AUTOSAR XML (schema 4-0-3)
package /ComponentTypes
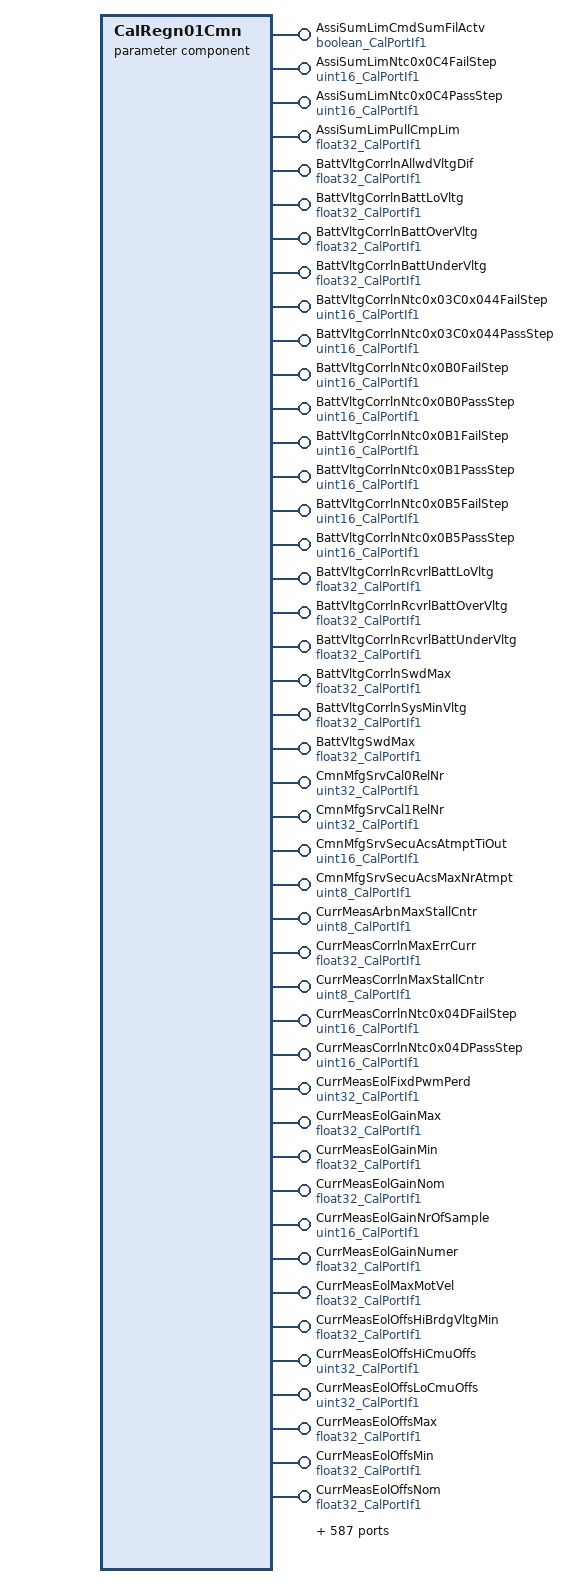
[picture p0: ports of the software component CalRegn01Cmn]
  parameter sw component type CalRegn01Cmn
    633 x provide port:
      AssiSumLimCmdSumFilActv: parameter-provide-com-spec{init-value=1, parameter=Logl}, provided-interface=boolean_CalPortIf1
      AssiSumLimNtc0x0C4FailStep: parameter-provide-com-spec{init-value=65535, parameter=Val}, provided-interface=uint16_CalPortIf1
      AssiSumLimNtc0x0C4PassStep: parameter-provide-com-spec{init-value=65535, parameter=Val}, provided-interface=uint16_CalPortIf1
      AssiSumLimPullCmpLim: parameter-provide-com-spec{init-value=8.8, parameter=Val}, provided-interface=float32_CalPortIf1
      BattVltgCorrlnAllwdVltgDif: parameter-provide-com-spec{init-value=0.73, parameter=Val}, provided-interface=float32_CalPortIf1
      BattVltgCorrlnBattLoVltg: parameter-provide-com-spec{init-value=10, parameter=Val}, provided-interface=float32_CalPortIf1
      BattVltgCorrlnBattOverVltg: parameter-provide-com-spec{init-value=16, parameter=Val}, provided-interface=float32_CalPortIf1
      BattVltgCorrlnBattUnderVltg: parameter-provide-com-spec{init-value=9, parameter=Val}, provided-interface=float32_CalPortIf1
      BattVltgCorrlnNtc0x03C0x044FailStep: parameter-provide-com-spec{init-value=410, parameter=Val}, provided-interface=uint16_CalPortIf1
      BattVltgCorrlnNtc0x03C0x044PassStep: parameter-provide-com-spec{init-value=272, parameter=Val}, provided-interface=uint16_CalPortIf1
      BattVltgCorrlnNtc0x0B0FailStep: parameter-provide-com-spec{init-value=327, parameter=Val}, provided-interface=uint16_CalPortIf1
      BattVltgCorrlnNtc0x0B0PassStep: parameter-provide-com-spec{init-value=327, parameter=Val}, provided-interface=uint16_CalPortIf1
      BattVltgCorrlnNtc0x0B1FailStep: parameter-provide-com-spec{init-value=327, parameter=Val}, provided-interface=uint16_CalPortIf1
      BattVltgCorrlnNtc0x0B1PassStep: parameter-provide-com-spec{init-value=327, parameter=Val}, provided-interface=uint16_CalPortIf1
      BattVltgCorrlnNtc0x0B5FailStep: parameter-provide-com-spec{init-value=327, parameter=Val}, provided-interface=uint16_CalPortIf1
      BattVltgCorrlnNtc0x0B5PassStep: parameter-provide-com-spec{init-value=327, parameter=Val}, provided-interface=uint16_CalPortIf1
      BattVltgCorrlnRcvrlBattLoVltg: parameter-provide-com-spec{init-value=10.5, parameter=Val}, provided-interface=float32_CalPortIf1
      BattVltgCorrlnRcvrlBattOverVltg: parameter-provide-com-spec{init-value=15.5, parameter=Val}, provided-interface=float32_CalPortIf1
      BattVltgCorrlnRcvrlBattUnderVltg: parameter-provide-com-spec{init-value=9.5, parameter=Val}, provided-interface=float32_CalPortIf1
      BattVltgCorrlnSwdMax: parameter-provide-com-spec{init-value=16, parameter=Val}, provided-interface=float32_CalPortIf1
      BattVltgCorrlnSysMinVltg: parameter-provide-com-spec{init-value=6, parameter=Val}, provided-interface=float32_CalPortIf1
      BattVltgSwdMax: parameter-provide-com-spec{init-value=16, parameter=Val}, provided-interface=float32_CalPortIf1
      CmnMfgSrvCal0RelNr: parameter-provide-com-spec{init-value=0, parameter=Val}, provided-interface=uint32_CalPortIf1
      CmnMfgSrvCal1RelNr: parameter-provide-com-spec{init-value=0, parameter=Val}, provided-interface=uint32_CalPortIf1
      CmnMfgSrvSecuAcsAtmptTiOut: parameter-provide-com-spec{init-value=0, parameter=Val}, provided-interface=uint16_CalPortIf1
      CmnMfgSrvSecuAcsMaxNrAtmpt: parameter-provide-com-spec{init-value=0, parameter=Val}, provided-interface=uint8_CalPortIf1
      CurrMeasArbnMaxStallCntr: parameter-provide-com-spec{init-value=20, parameter=Val}, provided-interface=uint8_CalPortIf1
      CurrMeasCorrlnMaxErrCurr: parameter-provide-com-spec{init-value=12, parameter=Val}, provided-interface=float32_CalPortIf1
      CurrMeasCorrlnMaxStallCntr: parameter-provide-com-spec{init-value=200, parameter=Val}, provided-interface=uint8_CalPortIf1
      CurrMeasCorrlnNtc0x04DFailStep: parameter-provide-com-spec{init-value=512, parameter=Val}, provided-interface=uint16_CalPortIf1
      CurrMeasCorrlnNtc0x04DPassStep: parameter-provide-com-spec{init-value=512, parameter=Val}, provided-interface=uint16_CalPortIf1
      CurrMeasEolFixdPwmPerd: parameter-provide-com-spec{init-value=62500, parameter=Val}, provided-interface=uint32_CalPortIf1
      CurrMeasEolGainMax: parameter-provide-com-spec{init-value=76, parameter=Val}, provided-interface=float32_CalPortIf1
      CurrMeasEolGainMin: parameter-provide-com-spec{init-value=56, parameter=Val}, provided-interface=float32_CalPortIf1
      CurrMeasEolGainNom: parameter-provide-com-spec{init-value=66.66, parameter=Val}, provided-interface=float32_CalPortIf1
      CurrMeasEolGainNrOfSample: parameter-provide-com-spec{init-value=5, parameter=Val}, provided-interface=uint16_CalPortIf1
      CurrMeasEolGainNumer: parameter-provide-com-spec{init-value=45, parameter=Val}, provided-interface=float32_CalPortIf1
      CurrMeasEolMaxMotVel: parameter-provide-com-spec{init-value=16, parameter=Val}, provided-interface=float32_CalPortIf1
      CurrMeasEolOffsHiBrdgVltgMin: parameter-provide-com-spec{init-value=262500, parameter=Val}, provided-interface=float32_CalPortIf1
      CurrMeasEolOffsHiCmuOffs: parameter-provide-com-spec{init-value=50000, parameter=Val}, provided-interface=uint32_CalPortIf1
      CurrMeasEolOffsLoCmuOffs: parameter-provide-com-spec{init-value=6250, parameter=Val}, provided-interface=uint32_CalPortIf1
      CurrMeasEolOffsMax: parameter-provide-com-spec{init-value=2.8, parameter=Val}, provided-interface=float32_CalPortIf1
      CurrMeasEolOffsMin: parameter-provide-com-spec{init-value=2.3, parameter=Val}, provided-interface=float32_CalPortIf1
      CurrMeasEolOffsNom: parameter-provide-com-spec{init-value=2.5, parameter=Val}, provided-interface=float32_CalPortIf1
      CurrMeasEolOffsNrOfSample: parameter-provide-com-spec{init-value=20, parameter=Val}, provided-interface=uint16_CalPortIf1
      CurrMeasEolTranCntrThd: parameter-provide-com-spec{init-value=5, parameter=Val}, provided-interface=uint8_CalPortIf1
      CurrMeasMinRqrdPhaOnTi: parameter-provide-com-spec{init-value=11000, parameter=Val}, provided-interface=uint32_CalPortIf1
      CurrMeasMotAgCompuDly: parameter-provide-com-spec{init-value=30000, parameter=Val}, provided-interface=uint32_CalPortIf1
      CurrMeasMotCurrAdcVlyWrmIninMax: parameter-provide-com-spec{init-value=3, parameter=Val}, provided-interface=float32_CalPortIf1
      CurrMeasMotCurrAdcVlyWrmIninMin: parameter-provide-com-spec{init-value=2, parameter=Val}, provided-interface=float32_CalPortIf1
      CurrMeasNtc0x05DFailStep: parameter-provide-com-spec{init-value=16384, parameter=Val}, provided-interface=uint16_CalPortIf1
      CurrMeasNtc0x05DPassStep: parameter-provide-com-spec{init-value=16384, parameter=Val}, provided-interface=uint16_CalPortIf1
      DiagcMgrFltResp: parameter-provide-com-spec{init-value=[0, 34560, 34560, 34560, 34560, 34560, 34560, 34560, 34560, 34560, 34560, 34560, 34560, 34560, 34560, 34560, 34560, 34560, 34560, 34560, 34560, 34560, 34560, 34560, 34560, 34560, 34560, 34560, 34560, 34560, 34560, 34560, 34560, 34560, 34560, 34560, 34560, 34560, 34560, 34560, 34560, 34560, 34560, 34560, 34560, 34560, 34560, 34560, 34560, 34560, 34560, 34560, 34560, 34560, 34560, 34560, 34560, 34560, 34560, 34560, 34560, 34560, 34560, 34560, 34560, 34560, 34560, 34560, 34560, 34560, 34560, 34560, 34560, 34560, 34560, 34560, 34560, 34560, 34560, 34560, 34560, 34560, 34560, 34560, 34560, 34560, 34560, 34560, 34560, 34560, 34560, 34560, 34560, 34560, 34560, 34560, 34560, 34560, 34560, 34560, 34560, 34560, 34560, 34560, 34560, 34560, 34560, 34560, 34560, 34560, 34560, 34560, 34560, 34560, 34560, 34560, 34560, 34560, 34560, 34560, 34560, 34560, 34560, 34560, 34560, 34560, 34560, 34560, 34560, 34560, 34560, 34560, 34560, 34560, 34560, 34560, 34560, 34560, 34560, 34560, 34560, 34560, 34560, 34560, 34560, 34560, 34560, 34560, 34560, 34560, 34560, 34560, 34560, 34560, 34560, 34560, 34560, 34560, 34560, 34560, 34560, 34560, 34560, 34560, 34560, 34560, 34560, 34560, 34560, 34560, 34560, 34560, 34560, 34560, 34560, 34560, 34560, 34560, 34560, 34560, 34560, 34560, 34560, 34560, 34560, 34560, 34560, 34560, 34560, 34560, 34560, 34560, 34560, 34560, 34560, 34560, 34560, 34560, 34560, 34560, 34560, 34560, 34560, 34560, 34560, 34560, 34560, 34560, 34560, 34560, 34560, 34560, 34560, 34560, 34560, 34560, 34560, 34560, 34560, 34560, 34560, 34560, 34560, 34560, 34560, 34560, 34560, 34560, 34560, 34560, 34560, 34560, 34560, 34560, 34560, 34560, 34560, 34560, 34560, 34560, 34560, 34560, 34560, 34560, 34560, 34560, 34560, 34560, 34560, 34560, 34560, 34560, 34560, 34560, 34560, 34560, 34560, 34560, 34560, 34560, 34560, 34560, 34560, 34560, 34560, 34560, 34560, 34560, 34560, 34560, 34560, 34560, 34560, 34560, 34560, 34560, 34560, 34560, 34560, 34560, 34560, 34560, 34560, 34560, 34560, 34560, 34560, 34560, 34560, 34560, 34560, 34560, 34560, 34560, 34560, 34560, 34560, 34560, 34560, 34560, 34560, 34560, 34560, 34560, 34560, 34560, 34560, 34560, 34560, 34560, 34560, 34560, 34560, 34560, 34560, 34560, 34560, 34560, 34560, 34560, 34560, 34560, 34560, 34560, 34560, 34560, 34560, 34560, 34560, 34560, 34560, 34560, 34560, 34560, 34560, 34560, 34560, 34560, 34560, 34560, 34560, 34560, 34560, 34560, 34560, 34560, 34560, 34560, 34560, 34560, 34560, 34560, 34560, 34560, 34560, 34560, 34560, 34560, 34560, 34560, 34560, 34560, 34560, 34560, 34560, 34560, 34560, 34560, 34560, 34560, 34560, 34560, 34560, 34560, 34560, 34560, 34560, 34560, 34560, 34560, 34560, 34560, 34560, 34560, 34560, 34560, 34560, 34560, 34560, 34560, 34560, 34560, 34560, 34560, 34560, 34560, 34560, 34560, 34560, 34560, 34560, 34560, 34560, 34560, 34560, 34560, 34560, 34560, 34560, 34560, 34560, 34560, 34560, 34560, 34560, 34560, 34560, 34560, 34560, 34560, 34560, 34560, 34560, 34560, 34560, 34560, 34560, 34560, 34560, 34560, 34560, 34560, 34560, 34560, 34560, 34560, 34560, 34560, 34560, 34560, 34560, 34560, 34560, 34560, 34560, 34560, 34560, 34560, 34560, 34560, 34560, 34560, 34560, 34560, 34560, 34560, 34560, 34560, 34560, 34560, 34560, 34560, 34560, 34560, 34560, 34560, 34560, 34560, 34560, 34560, 34560, 34560, 34560, 34560, 34560, 34560, 34560, 34560, 34560, 34560, 34560, 34560, 34560, 34560, 34560, 34560, 34560, 34560, 34560, 34560, 34560, 34560, 34560, 34560, 34560, 34560, 34560, 34560, 34560, 34560, 34560, 34560, 34560, 34560, 34560, 34560, 34560, 34560, 34560, 34560, 34560, 34560], parameter=Ary1D}, provided-interface=Ary1D_u16_512_CalPortIf1
      DrvrTqEstimnMtrxA: parameter-provide-com-spec{init-value=[[-0.17159, 0.00010352, 1.1696, 0.00024516, 1.9834e-05], [-240.58, 0.060289, 240.53, 0.17028, 0.047148], [0.0018246, -4.2826e-06, 0.99616, 0.00025897, -2.8965e-07], [-6.1943, 0.014635, 5.9127, 0.11656, 0.00098854], [-70.875, -0.28572, 70.86, 0.053221, 0.98679]], parameter=Ary2D}, provided-interface=Ary2D_f32_5_5_CalPortIf1
      DrvrTqEstimnMtrxB: parameter-provide-com-spec{init-value=[[3.2994e-07, 0.0081464, 0.0019034, 0.0016485], [0.00045434, 1.6329, 0.0015119, 0.76734], [1.1488e-06, -2.4566e-05, 0.0019002, 0.001743], [0.0027499, 0.045004, 0.00025007, 0.86756], [0.0001448, 0.50816, -2.5948e-05, 0.23299]], parameter=Ary2D}, provided-interface=Ary2D_f32_5_4_CalPortIf1
      DrvrTqEstimnMtrxC: parameter-provide-com-spec{init-value=[0, 0, 0, 0, 1], parameter=Ary1D}, provided-interface=Ary1D_f32_5_CalPortIf1
      DrvrTqEstimnMtrxD: parameter-provide-com-spec{init-value=[0, 0, 0, 0], parameter=Ary1D}, provided-interface=Ary1D_f32_4_CalPortIf1
      DutyCycThermProtnAbsltCtrlTFetMtgtnTblX: parameter-provide-com-spec{init-value=[122, 123, 125, 127], parameter=Ary1D}, provided-interface=Ary1D_s15p0_4_CalPortIf1
      DutyCycThermProtnAbsltCtrlTTblX: parameter-provide-com-spec{init-value=[122, 123, 125, 127], parameter=Ary1D}, provided-interface=Ary1D_s15p0_4_CalPortIf1
      DutyCycThermProtnAbsltCtrlTTqFetMtgtnTblY: parameter-provide-com-spec{init-value=[346, 287, 234, 0], parameter=Ary1D}, provided-interface=Ary1D_u9p7_4_CalPortIf1
      DutyCycThermProtnAbsltCtrlTTqTblY: parameter-provide-com-spec{init-value=[346, 287, 234, 0], parameter=Ary1D}, provided-interface=Ary1D_u9p7_4_CalPortIf1
      DutyCycThermProtnAbsltCuTFetMtgtnTblX: parameter-provide-com-spec{init-value=[122, 123, 125, 127], parameter=Ary1D}, provided-interface=Ary1D_s15p0_4_CalPortIf1
      DutyCycThermProtnAbsltCuTTblX: parameter-provide-com-spec{init-value=[122, 123, 125, 127], parameter=Ary1D}, provided-interface=Ary1D_s15p0_4_CalPortIf1
      DutyCycThermProtnAbsltCuTTqFetMtgtnTblY: parameter-provide-com-spec{init-value=[346, 287, 234, 0], parameter=Ary1D}, provided-interface=Ary1D_u9p7_4_CalPortIf1
      DutyCycThermProtnAbsltCuTTqTblY: parameter-provide-com-spec{init-value=[346, 287, 234, 0], parameter=Ary1D}, provided-interface=Ary1D_u9p7_4_CalPortIf1
      DutyCycThermProtnAbsltMotVelBreakPt: parameter-provide-com-spec{init-value=1.375, parameter=Val}, provided-interface=float32_CalPortIf1
      DutyCycThermProtnAbsltTTqSlewHiLim: parameter-provide-com-spec{init-value=0.3, parameter=Val}, provided-interface=float32_CalPortIf1
      DutyCycThermProtnAbsltTTqSlewLoLim: parameter-provide-com-spec{init-value=0.3, parameter=Val}, provided-interface=float32_CalPortIf1
      DutyCycThermProtnCtrlT: parameter-provide-com-spec{init-value=70, parameter=Val}, provided-interface=float32_CalPortIf1
      DutyCycThermProtnCtrlTSeln: parameter-provide-com-spec{init-value=1, parameter=Logl}, provided-interface=boolean_CalPortIf1
      DutyCycThermProtnDutyCycFildThd: parameter-provide-com-spec{init-value=92, parameter=Val}, provided-interface=u16p0_CalPortIf1
      DutyCycThermProtnIgnOffCtrlEna: parameter-provide-com-spec{init-value=0, parameter=Logl}, provided-interface=boolean_CalPortIf1
      DutyCycThermProtnIgnOffMsgWaitTi: parameter-provide-com-spec{init-value=0.5, parameter=Val}, provided-interface=float32_CalPortIf1
      DutyCycThermProtnLstTblValNonStall: parameter-provide-com-spec{init-value=[[128, 128, 128, 44, 44], [128, 128, 128, 44, 44]], parameter=Ary2D}, provided-interface=Ary2D_u9p7_2_5_CalPortIf1
      DutyCycThermProtnLstTblValStall: parameter-provide-com-spec{init-value=[[124, 124, 124, 40, 40], [124, 124, 124, 40, 40]], parameter=Ary2D}, provided-interface=Ary2D_u9p7_2_5_CalPortIf1
      DutyCycThermProtnMotPrTSeln: parameter-provide-com-spec{init-value=1, parameter=Logl}, provided-interface=boolean_CalPortIf1
      DutyCycThermProtnMplr1FetMtgtnNonStallTblY: parameter-provide-com-spec{init-value=[127, 127, 127, 1630, 1630], parameter=Ary1D}, provided-interface=Ary1D_u3p13_5_CalPortIf1
      DutyCycThermProtnMplr1FetMtgtnStallTblY: parameter-provide-com-spec{init-value=[133, 133, 133, 180, 180], parameter=Ary1D}, provided-interface=Ary1D_u3p13_5_CalPortIf1
      DutyCycThermProtnMplr1NonStallTblY: parameter-provide-com-spec{init-value=[127, 127, 127, 1630, 1630], parameter=Ary1D}, provided-interface=Ary1D_u3p13_5_CalPortIf1
      DutyCycThermProtnMplr1StallTblY: parameter-provide-com-spec{init-value=[133, 133, 133, 180, 180], parameter=Ary1D}, provided-interface=Ary1D_u3p13_5_CalPortIf1
      DutyCycThermProtnMplr2FetMtgtnNonStallTblY: parameter-provide-com-spec{init-value=[159, 159, 159, 281, 281], parameter=Ary1D}, provided-interface=Ary1D_u3p13_5_CalPortIf1
      DutyCycThermProtnMplr2FetMtgtnStallTblY: parameter-provide-com-spec{init-value=[167, 167, 167, 310, 310], parameter=Ary1D}, provided-interface=Ary1D_u3p13_5_CalPortIf1
      DutyCycThermProtnMplr2NonStallTblY: parameter-provide-com-spec{init-value=[159, 159, 159, 281, 281], parameter=Ary1D}, provided-interface=Ary1D_u3p13_5_CalPortIf1
      DutyCycThermProtnMplr2StallTblY: parameter-provide-com-spec{init-value=[167, 167, 167, 310, 310], parameter=Ary1D}, provided-interface=Ary1D_u3p13_5_CalPortIf1
      DutyCycThermProtnMplr3FetMtgtnNonStallTblY: parameter-provide-com-spec{init-value=[199, 199, 199, 1282, 1282], parameter=Ary1D}, provided-interface=Ary1D_u3p13_5_CalPortIf1
      DutyCycThermProtnMplr3FetMtgtnStallTblY: parameter-provide-com-spec{init-value=[210, 210, 210, 1707, 1707], parameter=Ary1D}, provided-interface=Ary1D_u3p13_5_CalPortIf1
      DutyCycThermProtnMplr3NonStallTblY: parameter-provide-com-spec{init-value=[199, 199, 199, 1282, 1282], parameter=Ary1D}, provided-interface=Ary1D_u3p13_5_CalPortIf1
      DutyCycThermProtnMplr3StallTblY: parameter-provide-com-spec{init-value=[210, 210, 210, 1707, 1707], parameter=Ary1D}, provided-interface=Ary1D_u3p13_5_CalPortIf1
      DutyCycThermProtnMplr4FetMtgtnNonStallTblY: parameter-provide-com-spec{init-value=5 x 1, parameter=Ary1D}, provided-interface=Ary1D_u3p13_5_CalPortIf1
      DutyCycThermProtnMplr4FetMtgtnStallTblY: parameter-provide-com-spec{init-value=5 x 1, parameter=Ary1D}, provided-interface=Ary1D_u3p13_5_CalPortIf1
      DutyCycThermProtnMplr4NonStallTblY: parameter-provide-com-spec{init-value=5 x 1, parameter=Ary1D}, provided-interface=Ary1D_u3p13_5_CalPortIf1
      DutyCycThermProtnMplr4StallTblY: parameter-provide-com-spec{init-value=5 x 1, parameter=Ary1D}, provided-interface=Ary1D_u3p13_5_CalPortIf1
      DutyCycThermProtnMplr5FetMtgtnNonStallTblY: parameter-provide-com-spec{init-value=[998, 998, 998, 9535, 9535], parameter=Ary1D}, provided-interface=Ary1D_u3p13_5_CalPortIf1
      DutyCycThermProtnMplr5FetMtgtnStallTblY: parameter-provide-com-spec{init-value=[998, 998, 998, 9535, 9535], parameter=Ary1D}, provided-interface=Ary1D_u3p13_5_CalPortIf1
      DutyCycThermProtnMplr5NonStallTblY: parameter-provide-com-spec{init-value=[998, 998, 998, 9535, 9535], parameter=Ary1D}, provided-interface=Ary1D_u3p13_5_CalPortIf1
      DutyCycThermProtnMplr5StallTblY: parameter-provide-com-spec{init-value=[998, 998, 998, 9535, 9535], parameter=Ary1D}, provided-interface=Ary1D_u3p13_5_CalPortIf1
      DutyCycThermProtnMplr6FetMtgtnNonStallTblY: parameter-provide-com-spec{init-value=5 x 1, parameter=Ary1D}, provided-interface=Ary1D_u3p13_5_CalPortIf1
      DutyCycThermProtnMplr6FetMtgtnStallTblY: parameter-provide-com-spec{init-value=5 x 1, parameter=Ary1D}, provided-interface=Ary1D_u3p13_5_CalPortIf1
      DutyCycThermProtnMplr6NonStallTblY: parameter-provide-com-spec{init-value=5 x 1, parameter=Ary1D}, provided-interface=Ary1D_u3p13_5_CalPortIf1
      DutyCycThermProtnMplr6StallTblY: parameter-provide-com-spec{init-value=5 x 1, parameter=Ary1D}, provided-interface=Ary1D_u3p13_5_CalPortIf1
      DutyCycThermProtnMplrFetMtgtnTblX: parameter-provide-com-spec{init-value=[-40, 0, 83, 84, 85], parameter=Ary1D}, provided-interface=Ary1D_s15p0_5_CalPortIf1
      DutyCycThermProtnMplrTblX: parameter-provide-com-spec{init-value=[-40, 0, 83, 84, 85], parameter=Ary1D}, provided-interface=Ary1D_s15p0_5_CalPortIf1
      DutyCycThermProtnMplrTSeln: parameter-provide-com-spec{init-value=1, parameter=Logl}, provided-interface=boolean_CalPortIf1
      DutyCycThermProtnSlowFilTSeln: parameter-provide-com-spec{init-value=0, parameter=Logl}, provided-interface=boolean_CalPortIf1
      DutyCycThermProtnThermLimScaFac: parameter-provide-com-spec{init-value=0.5, parameter=Val}, provided-interface=float32_CalPortIf1
      DutyCycThermProtnThermLoadLimTblX: parameter-provide-com-spec{init-value=[[0, 76, 80, 84, 88, 92, 96, 100], [0, 76, 80, 84, 88, 92, 96, 100]], parameter=Ary2D}, provided-interface=Ary2D_u16p0_2_8_CalPortIf1
      DutyCycThermProtnThermLoadLimTblY: parameter-provide-com-spec{init-value=[[346, 346, 346, 346, 287, 234, 181, 128], [346, 346, 346, 346, 287, 234, 181, 128]], parameter=Ary2D}, provided-interface=Ary2D_u9p7_2_8_CalPortIf1
      DutyCycThermProtnTqCmdSlewDwn: parameter-provide-com-spec{init-value=0.3, parameter=Val}, provided-interface=float32_CalPortIf1
      DutyCycThermProtnTqCmdSlewUp: parameter-provide-com-spec{init-value=0.3, parameter=Val}, provided-interface=float32_CalPortIf1
      ElecPwrCnsCtrlrInpR: parameter-provide-com-spec{init-value=0.0005, parameter=Val}, provided-interface=float32_CalPortIf1
      FordMsg077BusHiSpdCanDtcInhbThd: parameter-provide-com-spec{init-value=2000, parameter=Val}, provided-interface=u16p0_CalPortIf1
      FordMsg077BusHiSpdLatACmpdInvldSigFaildThd: parameter-provide-com-spec{init-value=0, parameter=Val}, provided-interface=u16p0_CalPortIf1
      FordMsg077BusHiSpdLatACmpdInvldSigPassdThd: parameter-provide-com-spec{init-value=0, parameter=Val}, provided-interface=u16p0_CalPortIf1
      FordMsg077BusHiSpdLatACmpdVldMissThd: parameter-provide-com-spec{init-value=100, parameter=Val}, provided-interface=u16p0_CalPortIf1
      FordMsg077BusHiSpdLgtACmpdInvldSigFaildThd: parameter-provide-com-spec{init-value=0, parameter=Val}, provided-interface=u16p0_CalPortIf1
      FordMsg077BusHiSpdLgtACmpdInvldSigPassdThd: parameter-provide-com-spec{init-value=0, parameter=Val}, provided-interface=u16p0_CalPortIf1
      FordMsg077BusHiSpdLgtACmpdVldMissThd: parameter-provide-com-spec{init-value=100, parameter=Val}, provided-interface=u16p0_CalPortIf1
      FordMsg077BusHiSpdMissMsgFaildThd: parameter-provide-com-spec{init-value=100, parameter=Val}, provided-interface=u16p0_CalPortIf1
      FordMsg077BusHiSpdMissMsgPassdThd: parameter-provide-com-spec{init-value=0, parameter=Val}, provided-interface=u16p0_CalPortIf1
      FordMsg077BusHiSpdOverGndInvldSigFaildThd: parameter-provide-com-spec{init-value=0, parameter=Val}, provided-interface=u16p0_CalPortIf1
      FordMsg077BusHiSpdOverGndInvldSigPassdThd: parameter-provide-com-spec{init-value=0, parameter=Val}, provided-interface=u16p0_CalPortIf1
      FordMsg077BusHiSpdVehLatACmpdVldFaildThd: parameter-provide-com-spec{init-value=0, parameter=Val}, provided-interface=u16p0_CalPortIf1
      FordMsg077BusHiSpdVehLatACmpdVldPassdThd: parameter-provide-com-spec{init-value=5000, parameter=Val}, provided-interface=u16p0_CalPortIf1
      FordMsg077BusHiSpdVehLgtACmpdVldFaildThd: parameter-provide-com-spec{init-value=0, parameter=Val}, provided-interface=u16p0_CalPortIf1
      FordMsg077BusHiSpdVehLgtACmpdVldPassdThd: parameter-provide-com-spec{init-value=500, parameter=Val}, provided-interface=u16p0_CalPortIf1
      FordMsg077BusHiSpdVehSpdOverGndVldFaildThd: parameter-provide-com-spec{init-value=0, parameter=Val}, provided-interface=u16p0_CalPortIf1
      FordMsg077BusHiSpdVehSpdOverGndVldMissThd: parameter-provide-com-spec{init-value=100, parameter=Val}, provided-interface=u16p0_CalPortIf1
      FordMsg077BusHiSpdVehSpdOverGndVldPassdThd: parameter-provide-com-spec{init-value=0, parameter=Val}, provided-interface=u16p0_CalPortIf1
      FordMsg077BusHiSpdVehYawRateCmpdVldFaildThd: parameter-provide-com-spec{init-value=0, parameter=Val}, provided-interface=u16p0_CalPortIf1
      FordMsg077BusHiSpdVehYawRateCmpdVldPassdThd: parameter-provide-com-spec{init-value=5000, parameter=Val}, provided-interface=u16p0_CalPortIf1
      FordMsg077BusHiSpdYawRateCmpdInvldSigFaildThd: parameter-provide-com-spec{init-value=0, parameter=Val}, provided-interface=u16p0_CalPortIf1
      FordMsg077BusHiSpdYawRateCmpdInvldSigPassdThd: parameter-provide-com-spec{init-value=0, parameter=Val}, provided-interface=u16p0_CalPortIf1
      FordMsg077BusHiSpdYawRateCmpdVldMissThd: parameter-provide-com-spec{init-value=100, parameter=Val}, provided-interface=u16p0_CalPortIf1
      FordMsg07DBusHiSpdActBrkTqSigInvldPassdThd: parameter-provide-com-spec{init-value=0, parameter=Val}, provided-interface=uint16_CalPortIf1
      FordMsg07DBusHiSpdFordVehActBrkTqInvldThd: parameter-provide-com-spec{init-value=0, parameter=Val}, provided-interface=uint16_CalPortIf1
      FordMsg07DBusHiSpdFordVehActBrkTqVldThd: parameter-provide-com-spec{init-value=0, parameter=Val}, provided-interface=uint16_CalPortIf1
      FordMsg07DBusHiSpdFordVehBrkTqVldMissMsgThd: parameter-provide-com-spec{init-value=5000, parameter=Val}, provided-interface=uint16_CalPortIf1
      FordMsg07DBusHiSpdFordVehVertACmpdSigInvldThd: parameter-provide-com-spec{init-value=0, parameter=Val}, provided-interface=uint16_CalPortIf1
      FordMsg07DBusHiSpdFordVehVertACmpdSigVldThd: parameter-provide-com-spec{init-value=5000, parameter=Val}, provided-interface=uint16_CalPortIf1
      FordMsg07DBusHiSpdFordVehVertAVldMissMsgThd: parameter-provide-com-spec{init-value=5000, parameter=Val}, provided-interface=uint16_CalPortIf1
      FordMsg07DBusHiSpdMissMsgFaildThd: parameter-provide-com-spec{init-value=5000, parameter=Val}, provided-interface=uint16_CalPortIf1
      FordMsg07DBusHiSpdMissMsgPassdThd: parameter-provide-com-spec{init-value=0, parameter=Val}, provided-interface=uint16_CalPortIf1
      FordMsg07DBusHiSpdVehActTqBrkInvldFaildThd: parameter-provide-com-spec{init-value=0, parameter=Val}, provided-interface=uint16_CalPortIf1
      FordMsg07DBusHiSpdVertACmpdSigInvldFaildThd: parameter-provide-com-spec{init-value=0, parameter=Val}, provided-interface=uint16_CalPortIf1
      FordMsg07DBusHiSpdVertACmpdSigInvldPassdThd: parameter-provide-com-spec{init-value=0, parameter=Val}, provided-interface=uint16_CalPortIf1
      FordMsg083BusHiSpdFordVehTurnSigVldThd: parameter-provide-com-spec{init-value=0, parameter=Val}, provided-interface=uint16_CalPortIf1
      FordMsg083BusHiSpdMissMsgFaildThd: parameter-provide-com-spec{init-value=5000, parameter=Val}, provided-interface=uint16_CalPortIf1
      FordMsg083BusHiSpdMissMsgPassdThd: parameter-provide-com-spec{init-value=0, parameter=Val}, provided-interface=uint16_CalPortIf1
      FordMsg083BusHiSpdVehTurnSigVldMissMsgThd: parameter-provide-com-spec{init-value=5000, parameter=Val}, provided-interface=uint16_CalPortIf1
      FordMsg091BusHiSpdInvldMsgFaildThd: parameter-provide-com-spec{init-value=0, parameter=Val}, provided-interface=uint16_CalPortIf1
      FordMsg091BusHiSpdInvldMsgPassdThd: parameter-provide-com-spec{init-value=0, parameter=Val}, provided-interface=uint16_CalPortIf1
      FordMsg091BusHiSpdMissMsgFaildThd: parameter-provide-com-spec{init-value=100, parameter=Val}, provided-interface=uint16_CalPortIf1
      FordMsg091BusHiSpdMissMsgPassdThd: parameter-provide-com-spec{init-value=0, parameter=Val}, provided-interface=uint16_CalPortIf1
      FordMsg091BusHiSpdYawRateRawVldMissFaildThd: parameter-provide-com-spec{init-value=100, parameter=Val}, provided-interface=uint16_CalPortIf1
      FordMsg091BusHiSpdYawRateRawVldSigFaildThd: parameter-provide-com-spec{init-value=0, parameter=Val}, provided-interface=uint16_CalPortIf1
      FordMsg091BusHiSpdYawRateRawVldSigPassdThd: parameter-provide-com-spec{init-value=5000, parameter=Val}, provided-interface=uint16_CalPortIf1
      FordMsg167BusHiSpdMissMsgFaildTiThd: parameter-provide-com-spec{init-value=100, parameter=Val}, provided-interface=uint16_CalPortIf1
      FordMsg167BusHiSpdMissMsgPassdTiThd: parameter-provide-com-spec{init-value=0, parameter=Val}, provided-interface=uint16_CalPortIf1
      FordMsg167BusHiSpdPrpnWhlTqFaildTiThd: parameter-provide-com-spec{init-value=5000, parameter=Val}, provided-interface=uint16_CalPortIf1
      FordMsg167BusHiSpdPrpnWhlTqMissTiThd: parameter-provide-com-spec{init-value=0, parameter=Val}, provided-interface=uint16_CalPortIf1
      FordMsg167BusHiSpdPrpnWhlTqPassdTiThd: parameter-provide-com-spec{init-value=5000, parameter=Val}, provided-interface=uint16_CalPortIf1
      FordMsg167BusHiSpdPrpnWhlTqSigInvldFaildTiThd: parameter-provide-com-spec{init-value=0, parameter=Val}, provided-interface=uint16_CalPortIf1
      FordMsg167BusHiSpdPrpnWhlTqSigInvldPassdTiThd: parameter-provide-com-spec{init-value=0, parameter=Val}, provided-interface=uint16_CalPortIf1
      FordMsg202BusHiSpdEngModLoQlyVldFaildThd: parameter-provide-com-spec{init-value=0, parameter=Val}, provided-interface=uint16_CalPortIf1
      FordMsg202BusHiSpdEngModLoQlyVldMissThd: parameter-provide-com-spec{init-value=100, parameter=Val}, provided-interface=uint16_CalPortIf1
      FordMsg202BusHiSpdEngModLoQlyVldPassdThd: parameter-provide-com-spec{init-value=0, parameter=Val}, provided-interface=uint16_CalPortIf1
      FordMsg202BusHiSpdEngModlVldFaildThd: parameter-provide-com-spec{init-value=0, parameter=Val}, provided-interface=uint16_CalPortIf1
      FordMsg202BusHiSpdEngModlVldMissThd: parameter-provide-com-spec{init-value=100, parameter=Val}, provided-interface=uint16_CalPortIf1
      FordMsg202BusHiSpdGearRvsStsInvldFaildThd: parameter-provide-com-spec{init-value=0, parameter=Val}, provided-interface=uint16_CalPortIf1
      FordMsg202BusHiSpdGearRvsStsInvldPassdThd: parameter-provide-com-spec{init-value=0, parameter=Val}, provided-interface=uint16_CalPortIf1
      FordMsg202BusHiSpdGearRvsStsVldFaildThd: parameter-provide-com-spec{init-value=0, parameter=Val}, provided-interface=uint16_CalPortIf1
      FordMsg202BusHiSpdGearRvsStsVldMissThd: parameter-provide-com-spec{init-value=100, parameter=Val}, provided-interface=uint16_CalPortIf1
      FordMsg202BusHiSpdGearRvsStsVldPassdThd: parameter-provide-com-spec{init-value=0, parameter=Val}, provided-interface=uint16_CalPortIf1
      FordMsg202BusHiSpdMissMsgFaildAbsPrsntDisadThd: parameter-provide-com-spec{init-value=100, parameter=Val}, provided-interface=uint16_CalPortIf1
      FordMsg202BusHiSpdMissMsgFaildAbsPrsntEnadThd: parameter-provide-com-spec{init-value=100, parameter=Val}, provided-interface=uint16_CalPortIf1
      FordMsg202BusHiSpdMissMsgPassdThd: parameter-provide-com-spec{init-value=100, parameter=Val}, provided-interface=uint16_CalPortIf1
      FordMsg202BusHiSpdQlyFacEngModInvldFaildThd: parameter-provide-com-spec{init-value=0, parameter=Val}, provided-interface=uint16_CalPortIf1
      FordMsg202BusHiSpdQlyFacEngModInvldPassdThd: parameter-provide-com-spec{init-value=0, parameter=Val}, provided-interface=uint16_CalPortIf1
      FordMsg202BusHiSpdTrlrBackupAssiAvlVldMissThd: parameter-provide-com-spec{init-value=100, parameter=Val}, provided-interface=uint16_CalPortIf1
      FordMsg202BusHiSpdTrlrBackupAssiAvlVldPassdThd: parameter-provide-com-spec{init-value=0, parameter=Val}, provided-interface=uint16_CalPortIf1
      FordMsg213BusHiSpdAbsActvVldFaildThd: parameter-provide-com-spec{init-value=200, parameter=Val}, provided-interface=uint16_CalPortIf1
      FordMsg213BusHiSpdAbsActvVldPassdThd: parameter-provide-com-spec{init-value=0, parameter=Val}, provided-interface=uint16_CalPortIf1
      FordMsg213BusHiSpdEvasSteerAssiEnadThd: parameter-provide-com-spec{init-value=200, parameter=Val}, provided-interface=uint16_CalPortIf1
      FordMsg213BusHiSpdMissMsgFaildThd: parameter-provide-com-spec{init-value=5000, parameter=Val}, provided-interface=uint16_CalPortIf1
      FordMsg213BusHiSpdMissMsgPassdThd: parameter-provide-com-spec{init-value=0, parameter=Val}, provided-interface=uint16_CalPortIf1
      FordMsg215BusHiSpdFordVehTrlrAidModReqVldNotRxdTiThd: parameter-provide-com-spec{init-value=5000, parameter=Val}, provided-interface=uint16_CalPortIf1
      FordMsg215BusHiSpdFordVehTrlrAidModReqVldRxdTiThd: parameter-provide-com-spec{init-value=0, parameter=Val}, provided-interface=uint16_CalPortIf1
      FordMsg215BusHiSpdMissMsgFaildTiThd: parameter-provide-com-spec{init-value=5000, parameter=Val}, provided-interface=uint16_CalPortIf1
      FordMsg215BusHiSpdMissMsgPassdTiThd: parameter-provide-com-spec{init-value=0, parameter=Val}, provided-interface=uint16_CalPortIf1
      FordMsg216BusHiSpdFrntLeWhlCntrDirFaildTiThd: parameter-provide-com-spec{init-value=0, parameter=Val}, provided-interface=uint16_CalPortIf1
      FordMsg216BusHiSpdFrntLeWhlCntrDirPassdTiThd: parameter-provide-com-spec{init-value=0, parameter=Val}, provided-interface=uint16_CalPortIf1
      FordMsg216BusHiSpdFrntLeWhlVldMissMsgThd: parameter-provide-com-spec{init-value=5000, parameter=Val}, provided-interface=uint16_CalPortIf1
      FordMsg216BusHiSpdFrntRiWhlCntrDirFaildTiThd: parameter-provide-com-spec{init-value=0, parameter=Val}, provided-interface=uint16_CalPortIf1
      FordMsg216BusHiSpdFrntRiWhlCntrDirPassdTiThd: parameter-provide-com-spec{init-value=0, parameter=Val}, provided-interface=uint16_CalPortIf1
      FordMsg216BusHiSpdFrntRiWhlVldMissMsgThd: parameter-provide-com-spec{init-value=5000, parameter=Val}, provided-interface=uint16_CalPortIf1
      FordMsg216BusHiSpdMissMsgFaildTiThd: parameter-provide-com-spec{init-value=5000, parameter=Val}, provided-interface=uint16_CalPortIf1
      FordMsg216BusHiSpdMissMsgPassdTiThd: parameter-provide-com-spec{init-value=0, parameter=Val}, provided-interface=uint16_CalPortIf1
      FordMsg216BusHiSpdReLeWhlCntrDirFaildTiThd: parameter-provide-com-spec{init-value=0, parameter=Val}, provided-interface=uint16_CalPortIf1
      FordMsg216BusHiSpdReLeWhlCntrDirPassdTiThd: parameter-provide-com-spec{init-value=0, parameter=Val}, provided-interface=uint16_CalPortIf1
      FordMsg216BusHiSpdReLeWhlVldMissMsgThd: parameter-provide-com-spec{init-value=5000, parameter=Val}, provided-interface=uint16_CalPortIf1
      FordMsg216BusHiSpdReRiWhlCntrDirFaildTiThd: parameter-provide-com-spec{init-value=0, parameter=Val}, provided-interface=uint16_CalPortIf1
      FordMsg216BusHiSpdReRiWhlCntrDirPassdTiThd: parameter-provide-com-spec{init-value=0, parameter=Val}, provided-interface=uint16_CalPortIf1
      FordMsg216BusHiSpdReRiWhlVldMissMsgThd: parameter-provide-com-spec{init-value=5000, parameter=Val}, provided-interface=uint16_CalPortIf1
      FordMsg217BusHiSpdFrntLeWhlSpdInvldFaildThd: parameter-provide-com-spec{init-value=0, parameter=Val}, provided-interface=u16p0_CalPortIf1
      FordMsg217BusHiSpdFrntLeWhlSpdInvldPassdThd: parameter-provide-com-spec{init-value=0, parameter=Val}, provided-interface=u16p0_CalPortIf1
      FordMsg217BusHiSpdFrntLeWhlVldFaildThd: parameter-provide-com-spec{init-value=0, parameter=Val}, provided-interface=u16p0_CalPortIf1
      FordMsg217BusHiSpdFrntLeWhlVldMissThd: parameter-provide-com-spec{init-value=100, parameter=Val}, provided-interface=u16p0_CalPortIf1
      FordMsg217BusHiSpdFrntLeWhlVldPassdThd: parameter-provide-com-spec{init-value=0, parameter=Val}, provided-interface=u16p0_CalPortIf1
      FordMsg217BusHiSpdFrntRiWhlSpdInvldFaildThd: parameter-provide-com-spec{init-value=0, parameter=Val}, provided-interface=u16p0_CalPortIf1
      FordMsg217BusHiSpdFrntRiWhlSpdInvldPassdThd: parameter-provide-com-spec{init-value=0, parameter=Val}, provided-interface=u16p0_CalPortIf1
      FordMsg217BusHiSpdFrntRiWhlVldFaildThd: parameter-provide-com-spec{init-value=0, parameter=Val}, provided-interface=u16p0_CalPortIf1
      FordMsg217BusHiSpdFrntRiWhlVldMissThd: parameter-provide-com-spec{init-value=100, parameter=Val}, provided-interface=u16p0_CalPortIf1
      FordMsg217BusHiSpdFrntRiWhlVldPassdThd: parameter-provide-com-spec{init-value=0, parameter=Val}, provided-interface=u16p0_CalPortIf1
      FordMsg217BusHiSpdMissMsgFaildThd: parameter-provide-com-spec{init-value=100, parameter=Val}, provided-interface=u16p0_CalPortIf1
      FordMsg217BusHiSpdMissMsgPassdThd: parameter-provide-com-spec{init-value=0, parameter=Val}, provided-interface=u16p0_CalPortIf1
      FordMsg217BusHiSpdReLeWhlSpdInvldFaildThd: parameter-provide-com-spec{init-value=0, parameter=Val}, provided-interface=u16p0_CalPortIf1
      FordMsg217BusHiSpdReLeWhlSpdInvldPassdThd: parameter-provide-com-spec{init-value=0, parameter=Val}, provided-interface=u16p0_CalPortIf1
      FordMsg217BusHiSpdReLeWhlVldFaildThd: parameter-provide-com-spec{init-value=0, parameter=Val}, provided-interface=u16p0_CalPortIf1
      FordMsg217BusHiSpdReLeWhlVldMissThd: parameter-provide-com-spec{init-value=100, parameter=Val}, provided-interface=u16p0_CalPortIf1
      FordMsg217BusHiSpdReLeWhlVldPassdThd: parameter-provide-com-spec{init-value=0, parameter=Val}, provided-interface=u16p0_CalPortIf1
      FordMsg217BusHiSpdReRiWhlSpdInvldFaildThd: parameter-provide-com-spec{init-value=0, parameter=Val}, provided-interface=u16p0_CalPortIf1
      FordMsg217BusHiSpdReRiWhlSpdInvldPassdThd: parameter-provide-com-spec{init-value=0, parameter=Val}, provided-interface=u16p0_CalPortIf1
      FordMsg217BusHiSpdReRiWhlVldFaildThd: parameter-provide-com-spec{init-value=0, parameter=Val}, provided-interface=u16p0_CalPortIf1
      FordMsg217BusHiSpdReRiWhlVldMissThd: parameter-provide-com-spec{init-value=100, parameter=Val}, provided-interface=u16p0_CalPortIf1
      FordMsg217BusHiSpdReRiWhlVldPassdThd: parameter-provide-com-spec{init-value=0, parameter=Val}, provided-interface=u16p0_CalPortIf1
      FordMsg230BusHiSpdFordVehGearLvrPosnFaildTiThd: parameter-provide-com-spec{init-value=0, parameter=Val}, provided-interface=uint16_CalPortIf1
      FordMsg230BusHiSpdFordVehGearLvrPosnPassdTiThd: parameter-provide-com-spec{init-value=0, parameter=Val}, provided-interface=uint16_CalPortIf1
      FordMsg230BusHiSpdGearLvrPosnMissTiThd: parameter-provide-com-spec{init-value=5000, parameter=Val}, provided-interface=uint16_CalPortIf1
      FordMsg230BusHiSpdInvldSigFaildThd: parameter-provide-com-spec{init-value=0, parameter=Val}, provided-interface=uint16_CalPortIf1
      FordMsg230BusHiSpdInvldSigPassdThd: parameter-provide-com-spec{init-value=0, parameter=Val}, provided-interface=uint16_CalPortIf1
      FordMsg230BusHiSpdMissMsgFaildThd: parameter-provide-com-spec{init-value=5000, parameter=Val}, provided-interface=uint16_CalPortIf1
      FordMsg230BusHiSpdMissMsgPassdThd: parameter-provide-com-spec{init-value=0, parameter=Val}, provided-interface=uint16_CalPortIf1
      FordMsg2FDBusHiSpdFordVehEvasSteerAssiReqVldNotRxdTiThd: parameter-provide-com-spec{init-value=5000, parameter=Val}, provided-interface=uint16_CalPortIf1
      FordMsg2FDBusHiSpdFordVehEvasSteerAssiReqVldRxdTiThd: parameter-provide-com-spec{init-value=5000, parameter=Val}, provided-interface=uint16_CalPortIf1
      FordMsg2FDBusHiSpdMissMsgFaildTiThd: parameter-provide-com-spec{init-value=5000, parameter=Val}, provided-interface=uint16_CalPortIf1
      FordMsg2FDBusHiSpdMissMsgPassdTiThd: parameter-provide-com-spec{init-value=0, parameter=Val}, provided-interface=uint16_CalPortIf1
      FordMsg3B3BusHiSpdIgnStsVldFaildThd: parameter-provide-com-spec{init-value=0, parameter=Val}, provided-interface=u16p0_CalPortIf1
      FordMsg3B3BusHiSpdIgnStsVldMissThd: parameter-provide-com-spec{init-value=100, parameter=Val}, provided-interface=u16p0_CalPortIf1
      FordMsg3B3BusHiSpdIgnStsVldPassdThd: parameter-provide-com-spec{init-value=0, parameter=Val}, provided-interface=u16p0_CalPortIf1
      FordMsg3B3BusHiSpdInvldSigFaildThd: parameter-provide-com-spec{init-value=0, parameter=Val}, provided-interface=u16p0_CalPortIf1
      FordMsg3B3BusHiSpdInvldSigPassdThd: parameter-provide-com-spec{init-value=0, parameter=Val}, provided-interface=u16p0_CalPortIf1
      FordMsg3B3BusHiSpdMissMsgFaildThd: parameter-provide-com-spec{init-value=100, parameter=Val}, provided-interface=u16p0_CalPortIf1
      FordMsg3B3BusHiSpdMissMsgPassdThd: parameter-provide-com-spec{init-value=0, parameter=Val}, provided-interface=u16p0_CalPortIf1
      FordMsg3CABusHiSpdLaneAssiImgProcgModlAFaildCrvtTiThd: parameter-provide-com-spec{init-value=0, parameter=Val}, provided-interface=uint16_CalPortIf1
      FordMsg3CABusHiSpdLaneAssiImgProcgModlAFaildReqdAgTiThd: parameter-provide-com-spec{init-value=0, parameter=Val}, provided-interface=uint16_CalPortIf1
      FordMsg3CABusHiSpdLaneAssiImgProcgModlAPassdTiThd: parameter-provide-com-spec{init-value=5000, parameter=Val}, provided-interface=uint16_CalPortIf1
      FordMsg3CABusHiSpdLaneAssiImgProcgModlAVldMissTiThd: parameter-provide-com-spec{init-value=1000, parameter=Val}, provided-interface=uint16_CalPortIf1
      FordMsg3CABusHiSpdLaneKeepSysCrvtInvldFaildTiThd: parameter-provide-com-spec{init-value=0, parameter=Val}, provided-interface=uint16_CalPortIf1
      FordMsg3CABusHiSpdLaneKeepSysCrvtInvldPassdTiThd: parameter-provide-com-spec{init-value=0, parameter=Val}, provided-interface=uint16_CalPortIf1
      FordMsg3CABusHiSpdLaneKeepSysReqdAgInvldFaildTiThd: parameter-provide-com-spec{init-value=0, parameter=Val}, provided-interface=uint16_CalPortIf1
      FordMsg3CABusHiSpdLaneKeepSysReqdAgInvldPassdTiThd: parameter-provide-com-spec{init-value=0, parameter=Val}, provided-interface=uint16_CalPortIf1
      FordMsg3CABusHiSpdMissMsgFaildTiThd: parameter-provide-com-spec{init-value=1000, parameter=Val}, provided-interface=uint16_CalPortIf1
      FordMsg3CABusHiSpdMissMsgPassdTiThd: parameter-provide-com-spec{init-value=0, parameter=Val}, provided-interface=uint16_CalPortIf1
      FordMsg3D3BusHiSpdImgProcrModlAVldFaildThd: parameter-provide-com-spec{init-value=1000, parameter=Val}, provided-interface=uint16_CalPortIf1
      FordMsg3D3BusHiSpdImgProcrModlAVldPassdThd: parameter-provide-com-spec{init-value=5000, parameter=Val}, provided-interface=uint16_CalPortIf1
      FordMsg3D3BusHiSpdMissMsgFaildThd: parameter-provide-com-spec{init-value=1000, parameter=Val}, provided-interface=uint16_CalPortIf1
      FordMsg3D3BusHiSpdMissMsgPassdThd: parameter-provide-com-spec{init-value=0, parameter=Val}, provided-interface=uint16_CalPortIf1
      FordMsg3D7BusHiSpdImgProcrModlAVldMissThd: parameter-provide-com-spec{init-value=500, parameter=Val}, provided-interface=uint16_CalPortIf1
      FordMsg3D7BusHiSpdImgProcrModlAVldPassdThd: parameter-provide-com-spec{init-value=5000, parameter=Val}, provided-interface=uint16_CalPortIf1
      FordMsg3D7BusHiSpdLatDstInvldFaildThd: parameter-provide-com-spec{init-value=0, parameter=Val}, provided-interface=uint16_CalPortIf1
      FordMsg3D7BusHiSpdLatDstInvldPassdThd: parameter-provide-com-spec{init-value=0, parameter=Val}, provided-interface=uint16_CalPortIf1
      FordMsg3D7BusHiSpdLatDstRawVldFaildThd: parameter-provide-com-spec{init-value=0, parameter=Val}, provided-interface=uint16_CalPortIf1
      FordMsg3D7BusHiSpdLgtDstInvldFaildThd: parameter-provide-com-spec{init-value=0, parameter=Val}, provided-interface=uint16_CalPortIf1
      FordMsg3D7BusHiSpdLgtDstInvldPassdThd: parameter-provide-com-spec{init-value=0, parameter=Val}, provided-interface=uint16_CalPortIf1
      FordMsg3D7BusHiSpdLgtDstRawVldFaildThd: parameter-provide-com-spec{init-value=0, parameter=Val}, provided-interface=uint16_CalPortIf1
      FordMsg3D7BusHiSpdMissMsgFaildThd: parameter-provide-com-spec{init-value=500, parameter=Val}, provided-interface=uint16_CalPortIf1
      FordMsg3D7BusHiSpdMissMsgPassdThd: parameter-provide-com-spec{init-value=0, parameter=Val}, provided-interface=uint16_CalPortIf1
      FordMsg3D7BusHiSpdRelLatVelInvldFaildThd: parameter-provide-com-spec{init-value=0, parameter=Val}, provided-interface=uint16_CalPortIf1
      FordMsg3D7BusHiSpdRelLatVelInvldPassdThd: parameter-provide-com-spec{init-value=0, parameter=Val}, provided-interface=uint16_CalPortIf1
      FordMsg3D7BusHiSpdRelLatVelRawVldFaildThd: parameter-provide-com-spec{init-value=0, parameter=Val}, provided-interface=uint16_CalPortIf1
      FordMsg3D7BusHiSpdRelLgtVelInvldFaildThd: parameter-provide-com-spec{init-value=0, parameter=Val}, provided-interface=uint16_CalPortIf1
      FordMsg3D7BusHiSpdRelLgtVelInvldPassdThd: parameter-provide-com-spec{init-value=0, parameter=Val}, provided-interface=uint16_CalPortIf1
      FordMsg3D7BusHiSpdRelLgtVelRawVldFaildThd: parameter-provide-com-spec{init-value=0, parameter=Val}, provided-interface=uint16_CalPortIf1
      FordMsg3D7BusHiSpdTiToCllsnInvldFaildThd: parameter-provide-com-spec{init-value=0, parameter=Val}, provided-interface=uint16_CalPortIf1
      FordMsg3D7BusHiSpdTiToCllsnInvldPassdThd: parameter-provide-com-spec{init-value=0, parameter=Val}, provided-interface=uint16_CalPortIf1
      FordMsg3D7BusHiSpdTiToCllsnRawVldFaildThd: parameter-provide-com-spec{init-value=0, parameter=Val}, provided-interface=uint16_CalPortIf1
      FordMsg40ABusHiSpdMissMsgFaildThd: parameter-provide-com-spec{init-value=5000, parameter=Val}, provided-interface=u16p0_CalPortIf1
      FordMsg40ABusHiSpdMissMsgPassdThd: parameter-provide-com-spec{init-value=0, parameter=Val}, provided-interface=u16p0_CalPortIf1
      FordMsg414BusHiSpdAgOffsVldFaildThd: parameter-provide-com-spec{init-value=0, parameter=Val}, provided-interface=uint16_CalPortIf1
      FordMsg414BusHiSpdAgOffsVldMissThd: parameter-provide-com-spec{init-value=1000, parameter=Val}, provided-interface=uint16_CalPortIf1
      FordMsg414BusHiSpdAgOffsVldPassdThd: parameter-provide-com-spec{init-value=0, parameter=Val}, provided-interface=uint16_CalPortIf1
      FordMsg414BusHiSpdChksVldFaildThd: parameter-provide-com-spec{init-value=0, parameter=Val}, provided-interface=uint16_CalPortIf1
      FordMsg414BusHiSpdChksVldMissThd: parameter-provide-com-spec{init-value=0, parameter=Val}, provided-interface=uint16_CalPortIf1
      FordMsg414BusHiSpdCntrVldMissThd: parameter-provide-com-spec{init-value=0, parameter=Val}, provided-interface=uint16_CalPortIf1
      FordMsg415BusHiSpdBrkModlLoQlyVldFaildThd: parameter-provide-com-spec{init-value=0, parameter=Val}, provided-interface=uint16_CalPortIf1
      FordMsg415BusHiSpdBrkModlLoQlyVldMissThd: parameter-provide-com-spec{init-value=0, parameter=Val}, provided-interface=uint16_CalPortIf1
      FordMsg415BusHiSpdBrkModlLoQlyVldPassdThd: parameter-provide-com-spec{init-value=0, parameter=Val}, provided-interface=uint16_CalPortIf1
      FordMsg415BusHiSpdBrkModlVldFaildThd: parameter-provide-com-spec{init-value=0, parameter=Val}, provided-interface=uint16_CalPortIf1
      FordMsg415BusHiSpdBrkModlVldMissThd: parameter-provide-com-spec{init-value=0, parameter=Val}, provided-interface=uint16_CalPortIf1
      FordMsg415BusHiSpdBrkModlVldPassdThd: parameter-provide-com-spec{init-value=0, parameter=Val}, provided-interface=uint16_CalPortIf1
      FordMsg415BusHiSpdBrkSprtVldMissThd: parameter-provide-com-spec{init-value=0, parameter=Val}, provided-interface=uint16_CalPortIf1
      FordMsg415BusHiSpdBrkSprtVldPassdThd: parameter-provide-com-spec{init-value=0, parameter=Val}, provided-interface=uint16_CalPortIf1
      FordMsg415BusHiSpdChksBrkModlInvldFaildThd: parameter-provide-com-spec{init-value=0, parameter=Val}, provided-interface=uint16_CalPortIf1
      FordMsg415BusHiSpdChksBrkModlInvldPassdThd: parameter-provide-com-spec{init-value=0, parameter=Val}, provided-interface=uint16_CalPortIf1
      FordMsg415BusHiSpdCntrBrkModlInvldFaildThd: parameter-provide-com-spec{init-value=0, parameter=Val}, provided-interface=uint16_CalPortIf1
      FordMsg415BusHiSpdCntrBrkModlInvldPassdThd: parameter-provide-com-spec{init-value=0, parameter=Val}, provided-interface=uint16_CalPortIf1
      FordMsg415BusHiSpdMissMsgFaildThd: parameter-provide-com-spec{init-value=100, parameter=Val}, provided-interface=uint16_CalPortIf1
      FordMsg415BusHiSpdMissMsgPassdThd: parameter-provide-com-spec{init-value=0, parameter=Val}, provided-interface=uint16_CalPortIf1
      FordMsg415BusHiSpdQlyFacBrkModlInvldFaildThd: parameter-provide-com-spec{init-value=0, parameter=Val}, provided-interface=uint16_CalPortIf1
      FordMsg415BusHiSpdQlyFacBrkModlInvldSigPassdThd: parameter-provide-com-spec{init-value=0, parameter=Val}, provided-interface=uint16_CalPortIf1
      FordMsg41ABusHiSpdMissMsgFaildThd: parameter-provide-com-spec{init-value=5000, parameter=Val}, provided-interface=uint16_CalPortIf1
      FordMsg41ABusHiSpdMissMsgPassdThd: parameter-provide-com-spec{init-value=0, parameter=Val}, provided-interface=uint16_CalPortIf1
      FordMsg41EBusHiSpdChassisVldMissFaildThd: parameter-provide-com-spec{init-value=5000, parameter=Val}, provided-interface=uint16_CalPortIf1
      FordMsg41EBusHiSpdChassisVldSigFaildThd: parameter-provide-com-spec{init-value=0, parameter=Val}, provided-interface=uint16_CalPortIf1
      FordMsg41EBusHiSpdChassisVldSigPassdThd: parameter-provide-com-spec{init-value=0, parameter=Val}, provided-interface=uint16_CalPortIf1
      FordMsg41EBusHiSpdInvldMsgFaildThd: parameter-provide-com-spec{init-value=0, parameter=Val}, provided-interface=uint16_CalPortIf1
      FordMsg41EBusHiSpdInvldMsgPassdThd: parameter-provide-com-spec{init-value=0, parameter=Val}, provided-interface=uint16_CalPortIf1
      FordMsg41EBusHiSpdMissMsgFaildThd: parameter-provide-com-spec{init-value=5000, parameter=Val}, provided-interface=uint16_CalPortIf1
      FordMsg41EBusHiSpdMissMsgPassdThd: parameter-provide-com-spec{init-value=0, parameter=Val}, provided-interface=uint16_CalPortIf1
      FordMsg430BusHiSpdMissMsgFaildThd: parameter-provide-com-spec{init-value=5000, parameter=Val}, provided-interface=u16p0_CalPortIf1
      FordMsg430BusHiSpdMissMsgPassdThd: parameter-provide-com-spec{init-value=0, parameter=Val}, provided-interface=u16p0_CalPortIf1
      FordMsg443BusHiSpdMissMsgFaildThd: parameter-provide-com-spec{init-value=5000, parameter=Val}, provided-interface=uint16_CalPortIf1
      FordMsg443BusHiSpdMissMsgPassdThd: parameter-provide-com-spec{init-value=0, parameter=Val}, provided-interface=uint16_CalPortIf1
      FordMsg459BusHiSpdDiagMsgMissTmrThd: parameter-provide-com-spec{init-value=5000, parameter=Val}, provided-interface=uint16_CalPortIf1
      FordMsg459BusHiSpdHitchAgInvldFaildThd: parameter-provide-com-spec{init-value=0, parameter=Val}, provided-interface=uint16_CalPortIf1
      FordMsg459BusHiSpdHitchAgInvldPassdThd: parameter-provide-com-spec{init-value=0, parameter=Val}, provided-interface=uint16_CalPortIf1
      FordMsg459BusHiSpdHitchAgRateInvldFaildThd: parameter-provide-com-spec{init-value=0, parameter=Val}, provided-interface=uint16_CalPortIf1
      FordMsg459BusHiSpdHitchAgRateInvldPassdThd: parameter-provide-com-spec{init-value=0, parameter=Val}, provided-interface=uint16_CalPortIf1
      FordMsg459BusHiSpdPrsntFlgMsgMissTmrThd: parameter-provide-com-spec{init-value=5000, parameter=Val}, provided-interface=uint16_CalPortIf1
      FordMsg459BusHiSpdRcvrDiagMsgMissTmrThd: parameter-provide-com-spec{init-value=0, parameter=Val}, provided-interface=uint16_CalPortIf1
      FordMsg459BusHiSpdRcvrPrsntFlgTmrThd: parameter-provide-com-spec{init-value=0, parameter=Val}, provided-interface=uint16_CalPortIf1
      FordMsg459BusHiSpdTrackStInvldFaildThd: parameter-provide-com-spec{init-value=0, parameter=Val}, provided-interface=uint16_CalPortIf1
      FordMsg459BusHiSpdTrackStInvldPassdThd: parameter-provide-com-spec{init-value=0, parameter=Val}, provided-interface=uint16_CalPortIf1
      FordMsg459BusHiSpdTrlrHitchAgVldInvldMsgThd: parameter-provide-com-spec{init-value=0, parameter=Val}, provided-interface=uint16_CalPortIf1
      FordMsg459BusHiSpdTrlrHitchAgVldMissMsgThd: parameter-provide-com-spec{init-value=5000, parameter=Val}, provided-interface=uint16_CalPortIf1
      FordMsg459BusHiSpdTrlrHitchRateVldInvldMsgThd: parameter-provide-com-spec{init-value=0, parameter=Val}, provided-interface=uint16_CalPortIf1
      FordMsg459BusHiSpdTrlrHitchRateVldMissMsgThd: parameter-provide-com-spec{init-value=5000, parameter=Val}, provided-interface=uint16_CalPortIf1
      FordMsg459BusHiSpdTrlrRcvrHitchAgVldThd: parameter-provide-com-spec{init-value=0, parameter=Val}, provided-interface=uint16_CalPortIf1
      FordMsg459BusHiSpdTrlrRcvrHitchRateVldThd: parameter-provide-com-spec{init-value=0, parameter=Val}, provided-interface=uint16_CalPortIf1
      FordMsg459BusHiSpdTrlrRcvrTarVldThd: parameter-provide-com-spec{init-value=0, parameter=Val}, provided-interface=uint16_CalPortIf1
      FordMsg459BusHiSpdTrlrRcvrTrackStVldThd: parameter-provide-com-spec{init-value=0, parameter=Val}, provided-interface=uint16_CalPortIf1
      FordMsg459BusHiSpdTrlrTarVldMissMsgThd: parameter-provide-com-spec{init-value=5000, parameter=Val}, provided-interface=uint16_CalPortIf1
      FordMsg459BusHiSpdTrlrTrackStVldInvldMsgThd: parameter-provide-com-spec{init-value=0, parameter=Val}, provided-interface=uint16_CalPortIf1
      FordMsg459BusHiSpdTrlrTrackStVldMissMsgThd: parameter-provide-com-spec{init-value=5000, parameter=Val}, provided-interface=uint16_CalPortIf1
      FordMsg47ABusHiSpdMissMsgFaildTiThd: parameter-provide-com-spec{init-value=100, parameter=Val}, provided-interface=uint16_CalPortIf1
      FordMsg47ABusHiSpdMissMsgPassdTiThd: parameter-provide-com-spec{init-value=0, parameter=Val}, provided-interface=uint16_CalPortIf1
      FordMsg47ABusHiSpdTrlrAidKnobBtnFaildTiThd: parameter-provide-com-spec{init-value=0, parameter=Val}, provided-interface=uint16_CalPortIf1
      FordMsg47ABusHiSpdTrlrAidKnobBtnInvldPassdTiThd: parameter-provide-com-spec{init-value=0, parameter=Val}, provided-interface=uint16_CalPortIf1
      FordMsg47ABusHiSpdTrlrAidKnobBtnMissTiThd: parameter-provide-com-spec{init-value=100, parameter=Val}, provided-interface=uint16_CalPortIf1
      FordMsg47ABusHiSpdTrlrAidKnobBtnPassdTiThd: parameter-provide-com-spec{init-value=100, parameter=Val}, provided-interface=uint16_CalPortIf1
      FordMsg47ABusHiSpdTrlrAidKnobPosFaildTiThd: parameter-provide-com-spec{init-value=0, parameter=Val}, provided-interface=uint16_CalPortIf1
      FordMsg47ABusHiSpdTrlrAidKnobPosInvldPassdTiThd: parameter-provide-com-spec{init-value=0, parameter=Val}, provided-interface=uint16_CalPortIf1
      FordMsg47ABusHiSpdTrlrAidKnobPosMissTiThd: parameter-provide-com-spec{init-value=100, parameter=Val}, provided-interface=uint16_CalPortIf1
      FordMsg47ABusHiSpdTrlrAidKnobPosPassdTiThd: parameter-provide-com-spec{init-value=100, parameter=Val}, provided-interface=uint16_CalPortIf1
      FordMsg4B0BusHiSpdCanDtcInhbTiThd: parameter-provide-com-spec{init-value=2000, parameter=Val}, provided-interface=u16p0_CalPortIf1
      FordMsg4B0BusHiSpdMsgFltNtcDiagcTiThd: parameter-provide-com-spec{init-value=0, parameter=Val}, provided-interface=u16p0_CalPortIf1
      FordMsg4B0BusHiSpdMsgFltTiThd: parameter-provide-com-spec{init-value=0, parameter=Val}, provided-interface=u16p0_CalPortIf1
      FordMsg4B0BusHiSpdMsgMissNtcDiagcTiThd: parameter-provide-com-spec{init-value=100, parameter=Val}, provided-interface=u16p0_CalPortIf1
      FordMsg4B0BusHiSpdMsgMissTiThd: parameter-provide-com-spec{init-value=10, parameter=Val}, provided-interface=u16p0_CalPortIf1
      FordMsg4B0BusHiSpdMsgRxdNtcDiagcTiThd: parameter-provide-com-spec{init-value=0, parameter=Val}, provided-interface=u16p0_CalPortIf1
      FordMsg4B0BusHiSpdMsgVldNtcDiagcTiThd: parameter-provide-com-spec{init-value=0, parameter=Val}, provided-interface=u16p0_CalPortIf1
      FordMsg4B0BusHiSpdMsgVldTiThd: parameter-provide-com-spec{init-value=5000, parameter=Val}, provided-interface=u16p0_CalPortIf1
      GateDrv0CtrlErrFilFrq: parameter-provide-com-spec{init-value=1.8, parameter=Val}, provided-interface=float32_CalPortIf1
      GateDrv0CtrlErrOffs: parameter-provide-com-spec{init-value=0, parameter=Val}, provided-interface=uint32_CalPortIf1
      GateDrv0CtrlErrThd: parameter-provide-com-spec{init-value=180000, parameter=Val}, provided-interface=uint32_CalPortIf1
      GateDrv0CtrlNtcNr0x050FailStep: parameter-provide-com-spec{init-value=4096, parameter=Val}, provided-interface=uint16_CalPortIf1
      GateDrv0CtrlNtcNr0x050PassStep: parameter-provide-com-spec{init-value=2048, parameter=Val}, provided-interface=uint16_CalPortIf1
      GateDrv0CtrlNtcNr0x051FailStep: parameter-provide-com-spec{init-value=4096, parameter=Val}, provided-interface=uint16_CalPortIf1
      GateDrv0CtrlNtcNr0x051PassStep: parameter-provide-com-spec{init-value=2048, parameter=Val}, provided-interface=uint16_CalPortIf1
      GateDrv0CtrlNtcNr0x055FailStep: parameter-provide-com-spec{init-value=4096, parameter=Val}, provided-interface=uint16_CalPortIf1
      GateDrv0CtrlNtcNr0x055PassStep: parameter-provide-com-spec{init-value=2048, parameter=Val}, provided-interface=uint16_CalPortIf1
      GateDrv0CtrlUnit0Cfg2WrVal: parameter-provide-com-spec{init-value=2832, parameter=Val}, provided-interface=uint16_CalPortIf1
      GateDrv0CtrlUnit0Cfg3WrVal: parameter-provide-com-spec{init-value=3598, parameter=Val}, provided-interface=uint16_CalPortIf1
      GateDrv0CtrlUnit0Cfg4WrVal: parameter-provide-com-spec{init-value=4622, parameter=Val}, provided-interface=uint16_CalPortIf1
      GateDrv0CtrlUnit0Cfg7WrVal: parameter-provide-com-spec{init-value=7924, parameter=Val}, provided-interface=uint16_CalPortIf1
      GtmCfgAndUseAdcStrtOfCnvn2Offs: parameter-provide-com-spec{init-value=25000, parameter=Val}, provided-interface=uint32_CalPortIf1
      GtmCfgAndUseAdcStrtOfCnvnPeakOffs: parameter-provide-com-spec{init-value=5000, parameter=Val}, provided-interface=uint32_CalPortIf1
      GtmCfgAndUseDma2MilliSecToMotCtrlTrig: parameter-provide-com-spec{init-value=25000, parameter=Val}, provided-interface=uint32_CalPortIf1
      GtmCfgAndUseDmaMotAgATrig: parameter-provide-com-spec{init-value=25000, parameter=Val}, provided-interface=uint32_CalPortIf1
      GtmCfgAndUseDmaMotCtrlTo2MilliSecTrig: parameter-provide-com-spec{init-value=25000, parameter=Val}, provided-interface=uint32_CalPortIf1
      GtmCfgAndUsePwmDbnd: parameter-provide-com-spec{init-value=200, parameter=Val}, provided-interface=uint32_CalPortIf1
      HwAgSnsrlsCorrdPinionAgConfThd: parameter-provide-com-spec{init-value=0.9, parameter=Val}, provided-interface=float32_CalPortIf1
      HwAgSnsrlsCorrdPinionAgHwConf: parameter-provide-com-spec{init-value=1, parameter=Val}, provided-interface=float32_CalPortIf1
      HwAgSnsrlsFCentrHwConf: parameter-provide-com-spec{init-value=1, parameter=Val}, provided-interface=float32_CalPortIf1
      HwAgSnsrlsMotAgIdptSigThd: parameter-provide-com-spec{init-value=1, parameter=Val}, provided-interface=uint8_CalPortIf1
      HwAgSnsrlsPinionTqFilFrq: parameter-provide-com-spec{init-value=0.035, parameter=Val}, provided-interface=float32_CalPortIf1
      HwAgSnsrlsRelHwAgFil1Frq: parameter-provide-com-spec{init-value=0.025, parameter=Val}, provided-interface=float32_CalPortIf1
      HwAgSnsrlsRelHwAgFil2Frq: parameter-provide-com-spec{init-value=0.025, parameter=Val}, provided-interface=float32_CalPortIf1
      HwAgSnsrlsSmotngCoeff: parameter-provide-com-spec{init-value=0.2, parameter=Val}, provided-interface=float32_CalPortIf1
      HwAgSnsrlsSmotngStepThd: parameter-provide-com-spec{init-value=5, parameter=Val}, provided-interface=float32_CalPortIf1
      HwAgSnsrlsStordPinionConf: parameter-provide-com-spec{init-value=0.1, parameter=Val}, provided-interface=float32_CalPortIf1
      HwAgSnsrlsStordPinionConfThd: parameter-provide-com-spec{init-value=0.1, parameter=Val}, provided-interface=float32_CalPortIf1
      HwAgSnsrlsVehDynDifThd: parameter-provide-com-spec{init-value=5, parameter=Val}, provided-interface=float32_CalPortIf1
      HwAgSnsrlsVehDynHwConf: parameter-provide-com-spec{init-value=0, parameter=Val}, provided-interface=float32_CalPortIf1
      HwAgSnsrlsVehDynMotVelThd: parameter-provide-com-spec{init-value=20, parameter=Val}, provided-interface=float32_CalPortIf1
      HwAgSnsrlsVehDynPinionTqThd: parameter-provide-com-spec{init-value=3, parameter=Val}, provided-interface=float32_CalPortIf1
      HwAgSnsrlsVehDynTmr1Thd: parameter-provide-com-spec{init-value=1500, parameter=Val}, provided-interface=uint32_CalPortIf1
      HwAgSnsrlsVehDynTmr2Thd: parameter-provide-com-spec{init-value=2000, parameter=Val}, provided-interface=uint32_CalPortIf1
      HwAgSnsrlsWhlFrqThd: parameter-provide-com-spec{init-value=0.2, parameter=Val}, provided-interface=float32_CalPortIf1
      HwAgSnsrlsWhlSpdHwAgCoeff1: parameter-provide-com-spec{init-value=4000, parameter=Val}, provided-interface=float32_CalPortIf1
      HwAgSnsrlsWhlSpdHwAgCoeff2: parameter-provide-com-spec{init-value=0, parameter=Val}, provided-interface=float32_CalPortIf1
      HwAgSnsrlsWhlSpdHwAgThd: parameter-provide-com-spec{init-value=600, parameter=Val}, provided-interface=float32_CalPortIf1
      HwAgSnsrlsWhlSpdHwConf: parameter-provide-com-spec{init-value=0.2, parameter=Val}, provided-interface=float32_CalPortIf1
      HwAgSnsrlsWhlSpdRatThd: parameter-provide-com-spec{init-value=1e-05, parameter=Val}, provided-interface=float32_CalPortIf1
      HwAgSnsrlsWhlSpdTmrThd: parameter-provide-com-spec{init-value=500, parameter=Val}, provided-interface=uint32_CalPortIf1
      HwAgSnsrlsWhlSpdVehSpdThd: parameter-provide-com-spec{init-value=0.1, parameter=Val}, provided-interface=float32_CalPortIf1
      HwAgSysArbnHwAgConf1Snsr: parameter-provide-com-spec{init-value=1, parameter=Val}, provided-interface=float32_CalPortIf1
      HwAgSysArbnHwAgConf1SnsrHwAgTrimNotPrfmd: parameter-provide-com-spec{init-value=0, parameter=Val}, provided-interface=float32_CalPortIf1
      HwAgSysArbnHwAgConf2Snsr: parameter-provide-com-spec{init-value=1, parameter=Val}, provided-interface=float32_CalPortIf1
      HwAgSysArbnHwAgConf2SnsrHwAgTrimNotPrfmd: parameter-provide-com-spec{init-value=0, parameter=Val}, provided-interface=float32_CalPortIf1
      HwAgSysArbnHwAgConfNoSnsr: parameter-provide-com-spec{init-value=0, parameter=Val}, provided-interface=float32_CalPortIf1
      HwAgSysArbnHwAgConfTiThd: parameter-provide-com-spec{init-value=5000, parameter=Val}, provided-interface=uint16_CalPortIf1
      HwAgSysArbnHwAgCorrdCorrlnThd: parameter-provide-com-spec{init-value=1, parameter=Val}, provided-interface=float32_CalPortIf1
      HwAgSysArbnHwAgCorrlnFailDebStep: parameter-provide-com-spec{init-value=132, parameter=Val}, provided-interface=uint16_CalPortIf1
      HwAgSysArbnHwAgCorrlnPassDebStep: parameter-provide-com-spec{init-value=132, parameter=Val}, provided-interface=uint16_CalPortIf1
      HwAgSysArbnHwAgCorrlnRng: parameter-provide-com-spec{init-value=5, parameter=Val}, provided-interface=float32_CalPortIf1
      HwAgSysArbnHwAgIdptSigLim: parameter-provide-com-spec{init-value=1, parameter=Val}, provided-interface=uint8_CalPortIf1
      HwAgSysArbnHwAgSlewRate: parameter-provide-com-spec{init-value=100, parameter=Val}, provided-interface=float32_CalPortIf1
      HwAgSysArbnHwAgSnsrlsCorrlnThd: parameter-provide-com-spec{init-value=1, parameter=Val}, provided-interface=float32_CalPortIf1
      HwAgSysArbnHwAgSnsrlsKineThd: parameter-provide-com-spec{init-value=1500, parameter=Val}, provided-interface=float32_CalPortIf1
      HwAgSysArbnImcHwAgCorrlnRng: parameter-provide-com-spec{init-value=5, parameter=Val}, provided-interface=float32_CalPortIf1
      HwAgSysArbnPinionAgConfThd: parameter-provide-com-spec{init-value=1, parameter=Val}, provided-interface=float32_CalPortIf1
      HwAgSysArbnSerlComHwAgCorrdConf: parameter-provide-com-spec{init-value=1, parameter=Val}, provided-interface=float32_CalPortIf1
      HwAgSysArbnSerlComHwAgSnsrlsConf: parameter-provide-com-spec{init-value=1, parameter=Val}, provided-interface=float32_CalPortIf1
      HwAgSysArbnSlewRateTmr: parameter-provide-com-spec{init-value=10000, parameter=Val}, provided-interface=float32_CalPortIf1
      HwTqArbnHwTqMaxStallCnt: parameter-provide-com-spec{init-value=200, parameter=Val}, provided-interface=uint8_CalPortIf1
      HwTqCorrlnImdtCorrlnChkFailThd: parameter-provide-com-spec{init-value=2.85, parameter=Val}, provided-interface=float32_CalPortIf1
      HwTqCorrlnNtcFailStep: parameter-provide-com-spec{init-value=3277, parameter=Val}, provided-interface=uint16_CalPortIf1
      HwTqCorrlnNtcPassStep: parameter-provide-com-spec{init-value=819, parameter=Val}, provided-interface=uint16_CalPortIf1
      ImcArbnEcuIninTiOutThd: parameter-provide-com-spec{init-value=500, parameter=Val}, provided-interface=uint32_CalPortIf1
      ImcArbnFrmFltThd: parameter-provide-com-spec{init-value=10, parameter=Val}, provided-interface=uint8_CalPortIf1
      LoaMgrCurrIvtrMtgtnScaZeroEna: parameter-provide-com-spec{init-value=0, parameter=Logl}, provided-interface=boolean_CalPortIf1
      LoaMgrCurrMeasIdptSig0Resp: parameter-provide-com-spec{init-value=2, parameter=Val}, provided-interface=uint8_CalPortIf1
      LoaMgrCurrMeasIdptSig1Resp: parameter-provide-com-spec{init-value=0, parameter=Val}, provided-interface=uint8_CalPortIf1
      LoaMgrCurrMeasIdptSig2Resp: parameter-provide-com-spec{init-value=0, parameter=Val}, provided-interface=uint8_CalPortIf1
      LoaMgrCurrMeasIdptSigFltThd: parameter-provide-com-spec{init-value=0, parameter=Val}, provided-interface=uint8_CalPortIf1
      LoaMgrCurrMeasMtgtnScaZeroEna: parameter-provide-com-spec{init-value=1, parameter=Logl}, provided-interface=boolean_CalPortIf1
      LoaMgrFadeOutStRate: parameter-provide-com-spec{init-value=1, parameter=Val}, provided-interface=float32_CalPortIf1
      LoaMgrHwTqIdptSig0NoTqLoaResp: parameter-provide-com-spec{init-value=4, parameter=Val}, provided-interface=uint8_CalPortIf1
      LoaMgrHwTqIdptSig1NoTqLoaResp: parameter-provide-com-spec{init-value=4, parameter=Val}, provided-interface=uint8_CalPortIf1
      LoaMgrHwTqIdptSig{2..4}Resp: parameter-provide-com-spec{init-value=0, parameter=Val}, provided-interface=uint8_CalPortIf1
      LoaMgrHwTqIdptSigFltThd: parameter-provide-com-spec{init-value=1, parameter=Val}, provided-interface=uint8_CalPortIf1
      LoaMgrHwTqLoaAvlResp: parameter-provide-com-spec{init-value=2, parameter=Val}, provided-interface=uint8_CalPortIf1
      LoaMgrIvtrIdptSig0Resp: parameter-provide-com-spec{init-value=5, parameter=Val}, provided-interface=uint8_CalPortIf1
      LoaMgrIvtrIdptSig1Resp: parameter-provide-com-spec{init-value=2, parameter=Val}, provided-interface=uint8_CalPortIf1
      LoaMgrIvtrIdptSig2Resp: parameter-provide-com-spec{init-value=0, parameter=Val}, provided-interface=uint8_CalPortIf1
      LoaMgrIvtrIdptSigFltThd: parameter-provide-com-spec{init-value=0, parameter=Val}, provided-interface=uint8_CalPortIf1
      LoaMgrIvtrMtgtnScaZeroEna: parameter-provide-com-spec{init-value=0, parameter=Logl}, provided-interface=boolean_CalPortIf1
      LoaMgrMotAgAvlSnsrlsResp: parameter-provide-com-spec{init-value=2, parameter=Val}, provided-interface=uint8_CalPortIf1
      LoaMgrMotAgIdptSig0NoSnsrlsResp: parameter-provide-com-spec{init-value=5, parameter=Val}, provided-interface=uint8_CalPortIf1
      LoaMgrMotAgIdptSig1NoSnsrlsResp: parameter-provide-com-spec{init-value=5, parameter=Val}, provided-interface=uint8_CalPortIf1
      LoaMgrMotAgIdptSig2Resp: parameter-provide-com-spec{init-value=1, parameter=Val}, provided-interface=uint8_CalPortIf1
      LoaMgrMotAgIdptSig3Resp: parameter-provide-com-spec{init-value=0, parameter=Val}, provided-interface=uint8_CalPortIf1
      LoaMgrMotAgIdptSigFltThd: parameter-provide-com-spec{init-value=2, parameter=Val}, provided-interface=uint8_CalPortIf1
      LoaMgrMotAgMtgtnScaZeroEna: parameter-provide-com-spec{init-value=0, parameter=Logl}, provided-interface=boolean_CalPortIf1
      MotAg2MeasOffs: parameter-provide-com-spec{init-value=0, parameter=Val}, provided-interface=float32_CalPortIf1
      MotAg5MeasAmpSqdMaxThd: parameter-provide-com-spec{init-value=2.8, parameter=Val}, provided-interface=float32_CalPortIf1
      MotAg5MeasAmpSqdMinThd: parameter-provide-com-spec{init-value=0.0625, parameter=Val}, provided-interface=float32_CalPortIf1
      MotAg5MeasLpFilFrq: parameter-provide-com-spec{init-value=0.1, parameter=Val}, provided-interface=float32_CalPortIf1
      MotAg5MeasOffs: parameter-provide-com-spec{init-value=0, parameter=Val}, provided-interface=u0p16_CalPortIf1
      MotAg5MeasRtAmpRecprLim: parameter-provide-com-spec{init-value=0.122, parameter=Val}, provided-interface=float32_CalPortIf1
      MotAg5MeasRtFilEnaThd: parameter-provide-com-spec{init-value=0.99, parameter=Val}, provided-interface=float32_CalPortIf1
      MotAg5MeasRtMotVelFilEnaThd: parameter-provide-com-spec{init-value=100, parameter=Val}, provided-interface=float32_CalPortIf1
      MotAg5MeasRtOffsLim: parameter-provide-com-spec{init-value=0.1, parameter=Val}, provided-interface=float32_CalPortIf1
      MotAg5MeasRtToNomRatLim: parameter-provide-com-spec{init-value=0.1, parameter=Val}, provided-interface=float32_CalPortIf1
      MotAg6MeasAmpSqdMaxThd: parameter-provide-com-spec{init-value=2.8, parameter=Val}, provided-interface=float32_CalPortIf1
      MotAg6MeasAmpSqdMinThd: parameter-provide-com-spec{init-value=0.0625, parameter=Val}, provided-interface=float32_CalPortIf1
      MotAg6MeasLpFilFrq: parameter-provide-com-spec{init-value=0.1, parameter=Val}, provided-interface=float32_CalPortIf1
      MotAg6MeasOffs: parameter-provide-com-spec{init-value=0, parameter=Val}, provided-interface=u0p16_CalPortIf1
      MotAg6MeasRtAmpRecprLim: parameter-provide-com-spec{init-value=0.122, parameter=Val}, provided-interface=float32_CalPortIf1
      MotAg6MeasRtFilEnaThd: parameter-provide-com-spec{init-value=0.99, parameter=Val}, provided-interface=float32_CalPortIf1
      MotAg6MeasRtMotVelFilEnaThd: parameter-provide-com-spec{init-value=100, parameter=Val}, provided-interface=float32_CalPortIf1
      MotAg6MeasRtOffsLim: parameter-provide-com-spec{init-value=0.1, parameter=Val}, provided-interface=float32_CalPortIf1
      MotAg6MeasRtToNomRatLim: parameter-provide-com-spec{init-value=0.1, parameter=Val}, provided-interface=float32_CalPortIf1
      MotAgSwCalVehSpdThd: parameter-provide-com-spec{init-value=3, parameter=Val}, provided-interface=float32_CalPortIf1
      MotCtrlPrmEstimnFetRNom: parameter-provide-com-spec{init-value=0.0052, parameter=Val}, provided-interface=float32_CalPortIf1
      MotCtrlPrmEstimnFetThermCoeff: parameter-provide-com-spec{init-value=0.005, parameter=Val}, provided-interface=float32_CalPortIf1
      MotCtrlPrmEstimnMagThermCoeff: parameter-provide-com-spec{init-value=-0.001, parameter=Val}, provided-interface=float32_CalPortIf1
      MotCtrlPrmEstimnMotBackEmfConHiLim: parameter-provide-com-spec{init-value=0.045, parameter=Val}, provided-interface=float32_CalPortIf1
      MotCtrlPrmEstimnMotBackEmfConLoLim: parameter-provide-com-spec{init-value=0.031, parameter=Val}, provided-interface=float32_CalPortIf1
      MotCtrlPrmEstimnMotBackEmfConNom: parameter-provide-com-spec{init-value=0.04, parameter=Val}, provided-interface=float32_CalPortIf1
      MotCtrlPrmEstimnMotBackEmfConSatnScaIvtrLoaMtgtn: parameter-provide-com-spec{init-value=1, parameter=Val}, provided-interface=float32_CalPortIf1
      MotCtrlPrmEstimnMotBackEmfConSatnX: parameter-provide-com-spec{init-value=[0, 1280, 2560, 3840, 5120, 6400, 7680, 8960, 10240, 11520, 12800, 14080, 15360, 16640, 19200, 21760], parameter=Ary1D}, provided-interface=Ary1D_u9p7_16_CalPortIf1
      MotCtrlPrmEstimnMotBackEmfConSatnY: parameter-provide-com-spec{init-value=[16384, 16384, 16384, 16384, 16384, 16384, 16384, 16384, 16384, 16384, 16384, 16370, 16336, 16276, 16095, 15869], parameter=Ary1D}, provided-interface=Ary1D_u2p14_16_CalPortIf1
      MotCtrlPrmEstimnMotCurrDaxInduSatnBilnrSeln: parameter-provide-com-spec{init-value=[0, 3200, 6400, 9600, 12800, 16000], parameter=Ary1D}, provided-interface=Ary1D_u9p7_6_CalPortIf1
      MotCtrlPrmEstimnMotCurrQaxInduSatnX: parameter-provide-com-spec{init-value=[0, 3200, 6400, 9600, 12800, 16000, 19200], parameter=Ary1D}, provided-interface=Ary1D_u9p7_7_CalPortIf1
      MotCtrlPrmEstimnMotInduDaxHiLim: parameter-provide-com-spec{init-value=0.00013, parameter=Val}, provided-interface=float32_CalPortIf1
      MotCtrlPrmEstimnMotInduDaxIvtrLoaMtgtn: parameter-provide-com-spec{init-value=0.00013, parameter=Val}, provided-interface=float32_CalPortIf1
      MotCtrlPrmEstimnMotInduDaxLoLim: parameter-provide-com-spec{init-value=0.0001, parameter=Val}, provided-interface=float32_CalPortIf1
      MotCtrlPrmEstimnMotInduDaxNom: parameter-provide-com-spec{init-value=0.00011889, parameter=Val}, provided-interface=float32_CalPortIf1
      MotCtrlPrmEstimnMotInduDaxSatnScaY: parameter-provide-com-spec{init-value=6 x [16384, 16384, 16384, 16384, 16384, 16305, 16096], parameter=Ary2D}, provided-interface=Ary2D_u2p14_6_7_CalPortIf1
      MotCtrlPrmEstimnMotInduQaxHiLim: parameter-provide-com-spec{init-value=0.00013, parameter=Val}, provided-interface=float32_CalPortIf1
      MotCtrlPrmEstimnMotInduQaxIvtrLoaMtgtn: parameter-provide-com-spec{init-value=0.00013, parameter=Val}, provided-interface=float32_CalPortIf1
      MotCtrlPrmEstimnMotInduQaxLoLim: parameter-provide-com-spec{init-value=0.0001, parameter=Val}, provided-interface=float32_CalPortIf1
      MotCtrlPrmEstimnMotInduQaxNom: parameter-provide-com-spec{init-value=0.00011889, parameter=Val}, provided-interface=float32_CalPortIf1
      MotCtrlPrmEstimnMotInduQaxSatnScaY: parameter-provide-com-spec{init-value=6 x [16384, 16384, 16384, 16384, 16384, 16305, 16096], parameter=Ary2D}, provided-interface=Ary2D_u2p14_6_7_CalPortIf1
      MotCtrlPrmEstimnMotRHiLim: parameter-provide-com-spec{init-value=0.032, parameter=Val}, provided-interface=float32_CalPortIf1
      MotCtrlPrmEstimnMotRLoLim: parameter-provide-com-spec{init-value=0.01246, parameter=Val}, provided-interface=float32_CalPortIf1
      MotCtrlPrmEstimnMotRNom: parameter-provide-com-spec{init-value=0.0139, parameter=Val}, provided-interface=float32_CalPortIf1
      MotCtrlPrmEstimnMotWidgThermCoeff: parameter-provide-com-spec{init-value=0.0039, parameter=Val}, provided-interface=float32_CalPortIf1
      MotCtrlPrmEstimnTNom: parameter-provide-com-spec{init-value=25, parameter=Val}, provided-interface=float32_CalPortIf1
      MotCurrPeakEstimnCurrFilFrq: parameter-provide-com-spec{init-value=8, parameter=Val}, provided-interface=float32_CalPortIf1
      MotCurrPeakEstimnCurrPeakEstimdFilFrq: parameter-provide-com-spec{init-value=0.03, parameter=Val}, provided-interface=float32_CalPortIf1
      MotCurrRegCfgCtrlrDynGainVehSpdCutOff: parameter-provide-com-spec{init-value=255, parameter=Val}, provided-interface=float32_CalPortIf1
      MotCurrRegCfgCurrLoopSecOrderTrfFctEna: parameter-provide-com-spec{init-value=1, parameter=Logl}, provided-interface=boolean_CalPortIf1
      MotCurrRegCfgIntglGainSampleTi: parameter-provide-com-spec{init-value=0.000125, parameter=Val}, provided-interface=float32_CalPortIf1
      MotCurrRegCfgMotAgCompuDly: parameter-provide-com-spec{init-value=9.375e-05, parameter=Val}, provided-interface=float32_CalPortIf1
      MotCurrRegCfgMotClsdLoopBwDaxY: parameter-provide-com-spec{init-value=[12800, 19200, 19200, 19200], parameter=Ary1D}, provided-interface=Ary1D_u10p6_4_CalPortIf1
      MotCurrRegCfgMotClsdLoopBwQaxY: parameter-provide-com-spec{init-value=[12800, 19200, 19200, 19200], parameter=Ary1D}, provided-interface=Ary1D_u10p6_4_CalPortIf1
      MotCurrRegCfgMotCtrlPrmSelnX: parameter-provide-com-spec{init-value=[0, 32, 160, 320], parameter=Ary1D}, provided-interface=Ary1D_u11p5_4_CalPortIf1
      MotCurrRegCfgMotDampgRatDax: parameter-provide-com-spec{init-value=1, parameter=Val}, provided-interface=float32_CalPortIf1
      MotCurrRegCfgMotDampgRatQax: parameter-provide-com-spec{init-value=1, parameter=Val}, provided-interface=float32_CalPortIf1
      MotCurrRegCfgMotNatFrqDaxY: parameter-provide-com-spec{init-value=[38400, 38400, 38400, 38400], parameter=Ary1D}, provided-interface=Ary1D_u9p7_4_CalPortIf1
      MotCurrRegCfgMotNatFrqQaxY: parameter-provide-com-spec{init-value=[38400, 38400, 38400, 38400], parameter=Ary1D}, provided-interface=Ary1D_u9p7_4_CalPortIf1
      MotCurrRegCfgMotRVirtDax: parameter-provide-com-spec{init-value=0, parameter=Val}, provided-interface=float32_CalPortIf1
      MotCurrRegCfgMotRVirtQax: parameter-provide-com-spec{init-value=0, parameter=Val}, provided-interface=float32_CalPortIf1
      MotCurrRegCfgMotVelFilFrq: parameter-provide-com-spec{init-value=10, parameter=Val}, provided-interface=float32_CalPortIf1
      MotCurrRegVltgLimrCurrLoaScarSlewRate: parameter-provide-com-spec{init-value=100, parameter=Val}, provided-interface=float32_CalPortIf1
      MotCurrRegVltgLimrDaxAntiWdupCoeff: parameter-provide-com-spec{init-value=0, parameter=Val}, provided-interface=float32_CalPortIf1
      MotCurrRegVltgLimrDualEcuLoaScarSlewRate: parameter-provide-com-spec{init-value=100, parameter=Val}, provided-interface=float32_CalPortIf1
      MotCurrRegVltgLimrFETLoaScarSlewRate: parameter-provide-com-spec{init-value=100, parameter=Val}, provided-interface=float32_CalPortIf1
      MotCurrRegVltgLimrIvtrLoaScarSlewRate: parameter-provide-com-spec{init-value=100, parameter=Val}, provided-interface=float32_CalPortIf1
      MotCurrRegVltgLimrMotCurrPredEna: parameter-provide-com-spec{init-value=0, parameter=Logl}, provided-interface=boolean_CalPortIf1
      MotCurrRegVltgLimrMotCurrPredTi: parameter-provide-com-spec{init-value=0, parameter=Val}, provided-interface=float32_CalPortIf1
      MotCurrRegVltgLimrMotCurrQaxRefMdfnRplEna: parameter-provide-com-spec{init-value=0, parameter=Logl}, provided-interface=boolean_CalPortIf1
      MotCurrRegVltgLimrMotVltgBrdgFilEna: parameter-provide-com-spec{init-value=1, parameter=Logl}, provided-interface=boolean_CalPortIf1
      MotCurrRegVltgLimrMotVltgBrdgLpFilFrq: parameter-provide-com-spec{init-value=200, parameter=Val}, provided-interface=float32_CalPortIf1
      MotCurrRegVltgLimrMotVltgDaxIntglHiLim: parameter-provide-com-spec{init-value=9, parameter=Val}, provided-interface=float32_CalPortIf1
      MotCurrRegVltgLimrMotVltgDaxIntglLoLim: parameter-provide-com-spec{init-value=-4.5, parameter=Val}, provided-interface=float32_CalPortIf1
      MotCurrRegVltgLimrMotVltgQaxFfFilEna: parameter-provide-com-spec{init-value=1, parameter=Logl}, provided-interface=boolean_CalPortIf1
      MotCurrRegVltgLimrMotVltgQaxFfLpFilFrq: parameter-provide-com-spec{init-value=500, parameter=Val}, provided-interface=float32_CalPortIf1
      MotCurrRegVltgLimrMotVltgQaxIntglHiLim: parameter-provide-com-spec{init-value=14.5, parameter=Val}, provided-interface=float32_CalPortIf1
      MotCurrRegVltgLimrMotVltgQaxIntglLoLim: parameter-provide-com-spec{init-value=-14.5, parameter=Val}, provided-interface=float32_CalPortIf1
      MotCurrRegVltgLimrQaxAntiWdupCoeff: parameter-provide-com-spec{init-value=0, parameter=Val}, provided-interface=float32_CalPortIf1
      MotCurrRegVltgLimrQaxAntiWdupScagDi: parameter-provide-com-spec{init-value=0, parameter=Logl}, provided-interface=boolean_CalPortIf1
      MotQuadDetnMotDirHysInsts: parameter-provide-com-spec{init-value=20480, parameter=Val}, provided-interface=s18p13_CalPortIf1
      MotRefMdlCurrDaxBoostGain: parameter-provide-com-spec{init-value=0, parameter=Val}, provided-interface=float32_CalPortIf1
      MotRefMdlCurrDaxBoostTqScaX: parameter-provide-com-spec{init-value=[0, 6144, 7168, 8192, 9216, 10240, 12288, 14336, 16384, 18432, 20480], parameter=Ary1D}, provided-interface=Ary1D_u4p12_11_CalPortIf1
      MotRefMdlCurrDaxBoostTqScaY: parameter-provide-com-spec{init-value=[0, 16384, 19661, 22938, 23757, 25395, 27034, 27853, 29491, 31130, 32768], parameter=Ary1D}, provided-interface=Ary1D_u1p15_11_CalPortIf1
      MotRefMdlCurrDaxQaxRefDelta: parameter-provide-com-spec{init-value=[-3.1415927, -2.3561945, -1.5707964, -0.7853982, 0, 0.7853982, 1.5707964, 2.3561945], parameter=Ary1D}, provided-interface=Ary1D_f32_8_CalPortIf1
      MotRefMdlCurrItrnTolr: parameter-provide-com-spec{init-value=0.1, parameter=Val}, provided-interface=float32_CalPortIf1
      MotRefMdlFbCtrlDi: parameter-provide-com-spec{init-value=0, parameter=Logl}, provided-interface=boolean_CalPortIf1
      MotRefMdlIvtrDeadTiBrdgVltgSca: parameter-provide-com-spec{init-value=1, parameter=Val}, provided-interface=float32_CalPortIf1
      MotRefMdlMinCurrItrnLim: parameter-provide-com-spec{init-value=3, parameter=Val}, provided-interface=uint8_CalPortIf1
      MotRefMdlMotCurrDaxMaxSca: parameter-provide-com-spec{init-value=1, parameter=Val}, provided-interface=float32_CalPortIf1
      MotRefMdlMotVelLpFilFrq: parameter-provide-com-spec{init-value=125, parameter=Val}, provided-interface=float32_CalPortIf1
      MotRefMdlMotVltgDerivtvTiCon: parameter-provide-com-spec{init-value=0.0026526, parameter=Val}, provided-interface=float32_CalPortIf1
      MotRefMdlQuad13VltgSdlX: parameter-provide-com-spec{init-value=[0, 3200, 6400, 9600, 16000, 19200, 22400, 25600, 28800, 35200], parameter=Ary1D}, provided-interface=Ary1D_u11p5_10_CalPortIf1
      MotRefMdlQuad13VltgSdlY: parameter-provide-com-spec{init-value=10 x 0, parameter=Ary1D}, provided-interface=Ary1D_u3p13_10_CalPortIf1
      MotRefMdlQuad24VltgSdlX: parameter-provide-com-spec{init-value=[0, 3200, 6400, 9600, 16000, 19200, 22400, 25600, 28800, 35200], parameter=Ary1D}, provided-interface=Ary1D_u11p5_10_CalPortIf1
      MotRefMdlQuad24VltgSdlY: parameter-provide-com-spec{init-value=10 x 0, parameter=Ary1D}, provided-interface=Ary1D_u3p13_10_CalPortIf1
      MotRefMdlRefLocnItrnLim: parameter-provide-com-spec{init-value=10, parameter=Val}, provided-interface=uint8_CalPortIf1
      MotRefMdlTqItrnLim: parameter-provide-com-spec{init-value=3, parameter=Val}, provided-interface=uint8_CalPortIf1
      MotRefMdlTqItrnTolr: parameter-provide-com-spec{init-value=0.015, parameter=Val}, provided-interface=float32_CalPortIf1
      MotRefMdlVltgModDynCmpEna: parameter-provide-com-spec{init-value=0, parameter=Logl}, provided-interface=boolean_CalPortIf1
      MotRefMdlVltgOverRThdSca: parameter-provide-com-spec{init-value=0.25, parameter=Val}, provided-interface=float32_CalPortIf1
      MotTqTranlDampgVehSpdBlndY: parameter-provide-com-spec{init-value=[16384, 16384, 0, 0], parameter=Ary1D}, provided-interface=Ary1D_u2p14_4_CalPortIf1
      NxtrCalIdsCal0DevlpAuthor: parameter-provide-com-spec{init-value=6 x 0, parameter=Ary1D}, provided-interface=Ary1D_u08_6_CalPortIf1
      NxtrCalIdsCal0DevlpDesc: parameter-provide-com-spec{init-value=48 x 0, parameter=Ary1D}, provided-interface=Ary1D_u08_48_CalPortIf1
      NxtrCalIdsCal0DevlpRelNr: parameter-provide-com-spec{init-value=0, parameter=Val}, provided-interface=uint32_CalPortIf1
      NxtrCalIdsCal0DevlpRelSt: parameter-provide-com-spec{init-value=0, parameter=Val}, provided-interface=uint8_CalPortIf1
      NxtrCalIdsCal0DevlpTiStamp: parameter-provide-com-spec{init-value=0, parameter=Val}, provided-interface=uint32_CalPortIf1
      NxtrCalIdsCal0DevlpVers: parameter-provide-com-spec{init-value=0, parameter=Val}, provided-interface=uint8_CalPortIf1
      NxtrCalIdsCal2DevlpAuthor: parameter-provide-com-spec{init-value=6 x 0, parameter=Ary1D}, provided-interface=Ary1D_u08_6_CalPortIf1
      NxtrCalIdsCal2DevlpDesc: parameter-provide-com-spec{init-value=48 x 0, parameter=Ary1D}, provided-interface=Ary1D_u08_48_CalPortIf1
      NxtrCalIdsCal2DevlpRelNr: parameter-provide-com-spec{init-value=0, parameter=Val}, provided-interface=uint32_CalPortIf1
      NxtrCalIdsCal2DevlpRelSt: parameter-provide-com-spec{init-value=0, parameter=Val}, provided-interface=uint8_CalPortIf1
      NxtrCalIdsCal2DevlpTiStamp: parameter-provide-com-spec{init-value=0, parameter=Val}, provided-interface=uint32_CalPortIf1
      NxtrCalIdsCal2DevlpVers: parameter-provide-com-spec{init-value=0, parameter=Val}, provided-interface=uint8_CalPortIf1
      PwrLimrAssiRednLpFilFrq: parameter-provide-com-spec{init-value=0.365, parameter=Val}, provided-interface=float32_CalPortIf1
      PwrLimrBackEmfConStdT: parameter-provide-com-spec{init-value=0.0335999, parameter=Val}, provided-interface=float32_CalPortIf1
      PwrLimrBrdgVltgAdjSlew: parameter-provide-com-spec{init-value=0.5, parameter=Val}, provided-interface=float32_CalPortIf1
      PwrLimrBrdgVltgAltFltAdj: parameter-provide-com-spec{init-value=1, parameter=Val}, provided-interface=float32_CalPortIf1
      PwrLimrFilAssiRednThd: parameter-provide-com-spec{init-value=0.6, parameter=Val}, provided-interface=float32_CalPortIf1
      PwrLimrLoVoltAssiRcvrThd: parameter-provide-com-spec{init-value=13.5, parameter=Val}, provided-interface=float32_CalPortIf1
      PwrLimrLoVoltAssiRcvrTi: parameter-provide-com-spec{init-value=2000, parameter=Val}, provided-interface=uint16_CalPortIf1
      PwrLimrMotEnvlpX: parameter-provide-com-spec{init-value=[-17600, -12800, -10400, -8800, -5657, -4600, -3499, -1731, 0, 1731, 3499, 4600, 5657, 8800], parameter=Ary1D}, provided-interface=Ary1D_s11p4_14_CalPortIf1
      PwrLimrMotEnvlpY: parameter-provide-com-spec{init-value=[1475, 2867, 3891, 4710, 7168, 8397, 9486, 9486, 9486, 9486, 7277, 5994, 4506, 0], parameter=Ary1D}, provided-interface=Ary1D_u5p11_14_CalPortIf1
      PwrLimrMotVelLpFilFrq: parameter-provide-com-spec{init-value=100, parameter=Val}, provided-interface=float32_CalPortIf1
      PwrLimrSpdAdjSlewDec: parameter-provide-com-spec{init-value=3.125, parameter=Val}, provided-interface=float32_CalPortIf1
      PwrLimrSpdAdjSlewEna: parameter-provide-com-spec{init-value=1, parameter=Logl}, provided-interface=boolean_CalPortIf1
      PwrLimrSpdAdjSlewInc: parameter-provide-com-spec{init-value=3125, parameter=Val}, provided-interface=float32_CalPortIf1
      PwrLimrStdOperMotEnvlpX: parameter-provide-com-spec{init-value=[0, 2182, 5717, 7919, 10034, 16320], parameter=Ary1D}, provided-interface=Ary1D_u11p5_6_CalPortIf1
      PwrLimrStdOperMotEnvlpY: parameter-provide-com-spec{init-value=[18973, 18973, 14553, 11989, 9011, 0], parameter=Ary1D}, provided-interface=Ary1D_u4p12_6_CalPortIf1
      PwrLimrVltgDptMotVelOffsX: parameter-provide-com-spec{init-value=[17496, 18728, 18928, 19136, 19336, 19544, 20568, 21592, 22208, 25280], parameter=Ary1D}, provided-interface=Ary1D_u5p11_10_CalPortIf1
      PwrLimrVltgDptMotVelOffsY: parameter-provide-com-spec{init-value=[3395, 2859, 2769, 2680, 2591, 2501, 2054, 1608, 1340, 0], parameter=Ary1D}, provided-interface=Ary1D_u11p5_10_CalPortIf1
      PwrSplyNtc0x07BFailStep: parameter-provide-com-spec{init-value=52424, parameter=Val}, provided-interface=uint16_CalPortIf1
      PwrSplyNtc0x07BPassStep: parameter-provide-com-spec{init-value=13106, parameter=Val}, provided-interface=uint16_CalPortIf1
      PwrSplyNtc0x07CFailStep: parameter-provide-com-spec{init-value=52424, parameter=Val}, provided-interface=uint16_CalPortIf1
      PwrSplyNtc0x07CPassStep: parameter-provide-com-spec{init-value=13106, parameter=Val}, provided-interface=uint16_CalPortIf1
      PwrSplyNtc0x07DFailStep: parameter-provide-com-spec{init-value=52424, parameter=Val}, provided-interface=uint16_CalPortIf1
      PwrSplyNtc0x07DPassStep: parameter-provide-com-spec{init-value=13106, parameter=Val}, provided-interface=uint16_CalPortIf1
      SinVltgGennDthrEna: parameter-provide-com-spec{init-value=1, parameter=Logl}, provided-interface=boolean_CalPortIf1
      SinVltgGennDthrLpFilCoeff: parameter-provide-com-spec{init-value=0.625, parameter=Val}, provided-interface=float32_CalPortIf1
      SysPrfmncStsAbsltCtrlTFltThd: parameter-provide-com-spec{init-value=91, parameter=Val}, provided-interface=float32_CalPortIf1
      SysPrfmncStsAssiStallLimDecThd: parameter-provide-com-spec{init-value=8.8, parameter=Val}, provided-interface=float32_CalPortIf1
      SysPrfmncStsBattDiagcHiCrit: parameter-provide-com-spec{init-value=18, parameter=Val}, provided-interface=float32_CalPortIf1
      SysPrfmncStsBattDiagcHiWarn: parameter-provide-com-spec{init-value=17.5, parameter=Val}, provided-interface=float32_CalPortIf1
      SysPrfmncStsBattDiagcLoCrit: parameter-provide-com-spec{init-value=9, parameter=Val}, provided-interface=float32_CalPortIf1
      SysPrfmncStsBattDiagcLoWarn: parameter-provide-com-spec{init-value=11.3, parameter=Val}, provided-interface=float32_CalPortIf1
      SysPrfmncStsBattVltgFilFrq: parameter-provide-com-spec{init-value=10, parameter=Val}, provided-interface=float32_CalPortIf1
      SysPrfmncStsDutyCycLvlFltThd: parameter-provide-com-spec{init-value=70, parameter=Val}, provided-interface=u16p0_CalPortIf1
      SysPrfmncStsLoadDptLimDecThd: parameter-provide-com-spec{init-value=8.8, parameter=Val}, provided-interface=float32_CalPortIf1
      SysPrfmncStsTDptLimThd: parameter-provide-com-spec{init-value=8.8, parameter=Val}, provided-interface=float32_CalPortIf1
      TEstimnIgnOffCtrlEna: parameter-provide-com-spec{init-value=0, parameter=Logl}, provided-interface=boolean_CalPortIf1
      TEstimnIgnOffMsgWaitTi: parameter-provide-com-spec{init-value=0.5, parameter=Val}, provided-interface=float32_CalPortIf1
      TqLoaDrvrTqNom: parameter-provide-com-spec{init-value=0.0117, parameter=Val}, provided-interface=float32_CalPortIf1
      TqLoaMotTqCmdLim: parameter-provide-com-spec{init-value=4.5, parameter=Val}, provided-interface=float32_CalPortIf1
      TqLoaMotVelAndTqBasdScaFacFallRate: parameter-provide-com-spec{init-value=-15.625, parameter=Val}, provided-interface=float32_CalPortIf1
      TqLoaMotVelAndTqBasdScaFacMax: parameter-provide-com-spec{init-value=1, parameter=Val}, provided-interface=float32_CalPortIf1
      TqLoaMotVelAndTqBasdScaFacMin: parameter-provide-com-spec{init-value=0.75, parameter=Val}, provided-interface=float32_CalPortIf1
      TqLoaMotVelAndTqBasdScaFacRiseRate: parameter-provide-com-spec{init-value=7.8125, parameter=Val}, provided-interface=float32_CalPortIf1
      TqLoaMotVelMgnThd: parameter-provide-com-spec{init-value=1.908, parameter=Val}, provided-interface=float32_CalPortIf1
      TqLoaTqCmdLimY: parameter-provide-com-spec{init-value=[2880, 2880, 2880, 2240, 1664, 1408, 1216, 832], parameter=Ary1D}, provided-interface=Ary1D_u4p12_8_CalPortIf1
      TqLoaTqCmdMgnThd: parameter-provide-com-spec{init-value=0, parameter=Val}, provided-interface=float32_CalPortIf1
      TqLoaVehLatADifScaFacFallRate: parameter-provide-com-spec{init-value=-4, parameter=Val}, provided-interface=float32_CalPortIf1
      TqLoaVehLatADifScaFacRiseRate: parameter-provide-com-spec{init-value=0.1, parameter=Val}, provided-interface=float32_CalPortIf1
      TqLoaVehLatADifScaFacX: parameter-provide-com-spec{init-value=[0, 2294, 5243, 16384], parameter=Ary1D}, provided-interface=Ary1D_u2p14_4_CalPortIf1
      TqLoaVehLatADifScaFacY: parameter-provide-com-spec{init-value=8 x [32768, 32768, 0, 0], parameter=Ary2D}, provided-interface=Ary2D_u1p15_8_4_CalPortIf1
      TqLoaVehLatAEstimnFilFrq: parameter-provide-com-spec{init-value=2, parameter=Val}, provided-interface=float32_CalPortIf1
      TqLoaVehLatAGainY: parameter-provide-com-spec{init-value=[0, 6144, 9920, 6784, 4928, 3968, 3520, 384], parameter=Ary1D}, provided-interface=Ary1D_u4p12_8_CalPortIf1
      TqLoaVehSpdScaFacX: parameter-provide-com-spec{init-value=[320, 640, 1920, 3840, 6400], parameter=Ary1D}, provided-interface=Ary1D_u10p6_5_CalPortIf1
      TqLoaVehSpdScaFacY: parameter-provide-com-spec{init-value=[0, 32768, 32768, 32768, 32768], parameter=Ary1D}, provided-interface=Ary1D_u1p15_5_CalPortIf1
      TqLoaVehSpdX: parameter-provide-com-spec{init-value=[320, 640, 1280, 1920, 2560, 3200, 3840, 7680], parameter=Ary1D}, provided-interface=Ary1D_u10p6_8_CalPortIf1
      TqLoaVehSteerRat: parameter-provide-com-spec{init-value=16, parameter=Val}, provided-interface=float32_CalPortIf1
      TqLoaVehUnderSteerGrdt: parameter-provide-com-spec{init-value=0.0211, parameter=Val}, provided-interface=float32_CalPortIf1
      TqLoaVehWhlBas: parameter-provide-com-spec{init-value=2.7305, parameter=Val}, provided-interface=float32_CalPortIf1
      VehSigCdngDftLatA: parameter-provide-com-spec{init-value=0, parameter=Val}, provided-interface=float32_CalPortIf1
      VehSigCdngDftLgtA: parameter-provide-com-spec{init-value=0, parameter=Val}, provided-interface=float32_CalPortIf1
      VehSigCdngDftVehSpd: parameter-provide-com-spec{init-value=100, parameter=Val}, provided-interface=float32_CalPortIf1
      VehSigCdngDftYawRate: parameter-provide-com-spec{init-value=0, parameter=Val}, provided-interface=float32_CalPortIf1
      VehSigCdngLatADifThd: parameter-provide-com-spec{init-value=0.2, parameter=Val}, provided-interface=float32_CalPortIf1
      VehSigCdngLatAFilFrq: parameter-provide-com-spec{init-value=100, parameter=Val}, provided-interface=float32_CalPortIf1
      VehSigCdngLtgADifThd: parameter-provide-com-spec{init-value=1, parameter=Val}, provided-interface=float32_CalPortIf1
      VehSigCdngVehSpdDifThd: parameter-provide-com-spec{init-value=5, parameter=Val}, provided-interface=float32_CalPortIf1
      VehSigCdngVehYawSlewRate: parameter-provide-com-spec{init-value=120, parameter=Val}, provided-interface=float32_CalPortIf1
      VehSigCdngYawRateDifThd: parameter-provide-com-spec{init-value=20, parameter=Val}, provided-interface=float32_CalPortIf1
      VehSpdLimrMaxAssiX: parameter-provide-com-spec{init-value=[0, 3200, 6400, 8320, 9600], parameter=Ary1D}, provided-interface=Ary1D_u9p7_5_CalPortIf1
      VehSpdLimrMaxAssiY: parameter-provide-com-spec{init-value=5 x 18022, parameter=Ary1D}, provided-interface=Ary1D_u5p11_5_CalPortIf1
      VehSpdLimrPosMaxOffs1: parameter-provide-com-spec{init-value=140, parameter=Val}, provided-interface=float32_CalPortIf1
      VehSpdLimrPosMaxOffs2: parameter-provide-com-spec{init-value=120, parameter=Val}, provided-interface=float32_CalPortIf1
